[part 2 of 2: package /ComponentTypes]
AUTOSAR XML (schema 00046)
package /ComponentTypes  (continued)
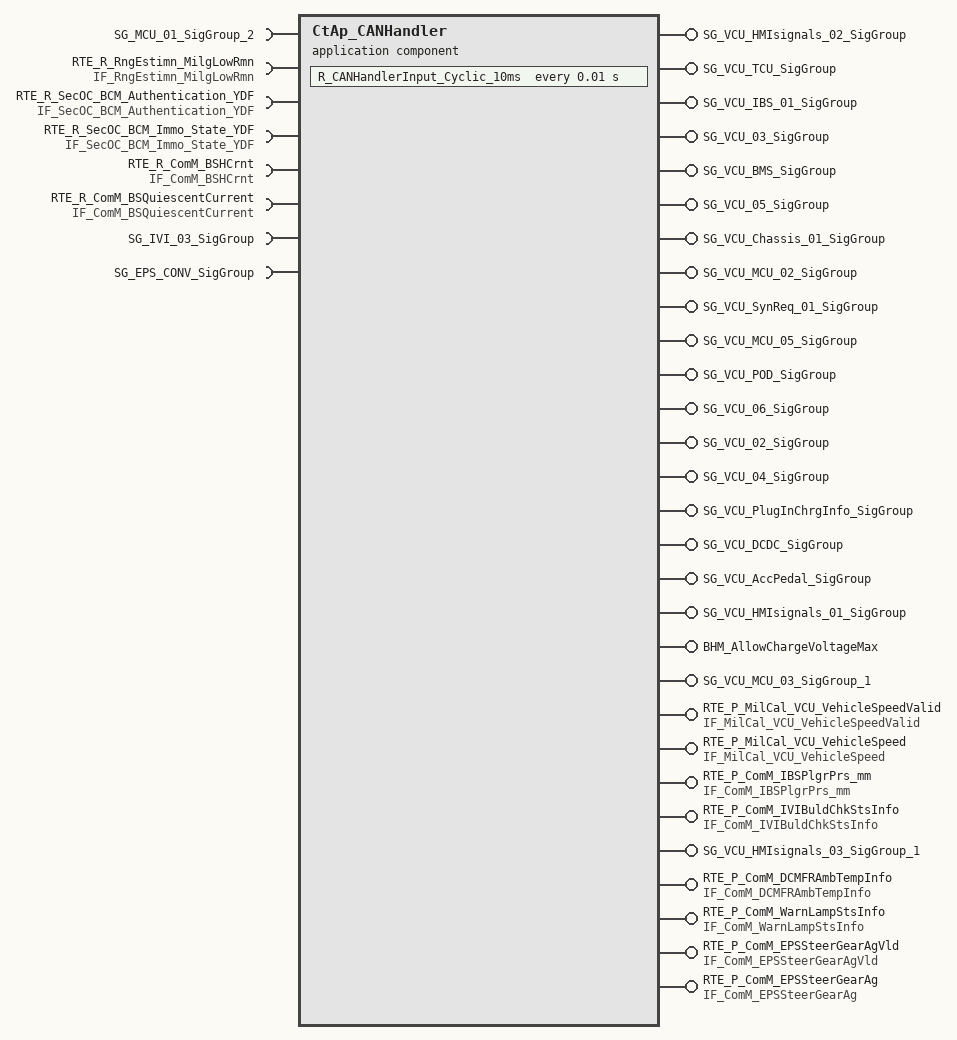
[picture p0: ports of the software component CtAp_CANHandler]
  application sw component type CtAp_CANHandler  (continued)
    19 x provide port:
      SG_VCU_HMIsignals_02_SigGroup: nonqueued-sender-com-spec{data-element=SG_VCU_HMIsignals_02_SigGroup, uses-end-to-end-protection=true, init-value=fields=[Checksum_318:0, MessageCounter_318:0, VCU_DischargeEndSoc:50, VCU_Display_Cur:0, VCU_Display_Power:0, VCU_ForwardVmaxAllowed:0, VCU_maxChargeSOC:255, VCU_MCU_FaultLampReq:0, VCU_SystemReady:0]}, provided-interface=SG_VCU_HMIsignals_02_SigGroup
      SG_VCU_TCU_SigGroup: nonqueued-sender-com-spec{data-element=SG_VCU_TCU_SigGroup, init-value=fields=[VCU_RequestedModeTCU:0, VCU_TCUPowerAllowed:0]}, provided-interface=SG_VCU_TCU_SigGroup
      SG_VCU_IBS_01_SigGroup: nonqueued-sender-com-spec{data-element=SG_VCU_IBS_01_SigGroup, uses-end-to-end-protection=true, init-value=fields=[Checksum_094:0, MessageCounter_094:0, VCU_MotorActualTorque:0, VCU_MotorActualTorqueValid:0, VCU_OPStandstillReq:0, VCU_WheelTrqACT:0, VCU_WheelTrqACTValid:0]}, provided-interface=SG_VCU_IBS_01_SigGroup
      SG_VCU_03_SigGroup: nonqueued-sender-com-spec{data-element=SG_VCU_03_SigGroup, init-value=fields=[VCU_BrakeCompensateStatus:0, VCU_ChargeProcessComment:0, VCU_DCFCCurrent:0, VCU_EnergyV2L:0, VCU_MemoryChargeFault:0]}, provided-interface=SG_VCU_03_SigGroup
      SG_VCU_BMS_SigGroup: nonqueued-sender-com-spec{data-element=SG_VCU_BMS_SigGroup, uses-end-to-end-protection=true, init-value=fields=[Checksum_0D1:0, MessageCounter_0D1:0, VCU_ActDriveMode:0, VCU_BMSTargetThermLevel:0, VCU_DrvModSwitchWarn:0, VCU_HVStatus:0, VCU_LimitLevel:0, VCU_RegenBrakeLightRequest:0, VCU_RegenBrakeLightReqVld:0, VCU_RequestedModeBMS:0, VCU_BMS_Control_of_PosRelay:0, VCU_ChargeStatus:0, VCU_IsoMeasurementSwitch:1]}, provided-interface=SG_VCU_BMS_SigGroup
      SG_VCU_05_SigGroup: nonqueued-sender-com-spec{data-element=SG_VCU_05_SigGroup, init-value=fields=[VCU_MaximumOutputCurrent:0, VCU_MaximumOutputVoltage:0, VCU_MinimumOutputCurrent:0, VCU_MinimumOutputVoltage:0]}, provided-interface=SG_VCU_05_SigGroup
      SG_VCU_Chassis_01_SigGroup: nonqueued-sender-com-spec{data-element=SG_VCU_Chassis_01_SigGroup, uses-end-to-end-protection=true, init-value=fields=[Checksum_0D3:0, MessageCounter_0D3:0, VCU_ADASOverride:0, VCU_APSTorqueRequestActive:0, VCU_APSTorqueRequestAvailable:0, VCU_BrakeCompensateWarn:0, VCU_DecelerationReq:0, VCU_DecelerationReqactive:0, VCU_DriverTorqueRequest:0, VCU_EnergyManagementWarn:0, VCU_RegenTorqueCap:0, VCU_RegenTorqueCapValid:0, VCU_RegStatus:0, VCU_TorqueRequestActive:0, VCU_TorqueRequestAvailable:0]}, provided-interface=SG_VCU_Chassis_01_SigGroup
      SG_VCU_MCU_02_SigGroup: nonqueued-sender-com-spec{data-element=SG_VCU_MCU_02_SigGroup, init-value=fields=[VCU_MaxSpdLimit:32767, VCU_MCUActHeatPwr:0, VCU_MotorSpdReq:32767]}, provided-interface=SG_VCU_MCU_02_SigGroup
      SG_VCU_SynReq_01_SigGroup: nonqueued-sender-com-spec{data-element=SG_VCU_SynReq_01_SigGroup, init-value=fields=VCU_SynRequest:16777215}, provided-interface=SG_VCU_SynReq_01_SigGroup
      SG_VCU_MCU_05_SigGroup: nonqueued-sender-com-spec{data-element=SG_VCU_MCU_05_SigGroup, init-value=fields=[VCU_MaxTorqueGradient:0, VCU_MaxTorqueLimit:0, VCU_MinTorqueLimit:0, VCU_CreepTorque:0, VCU_SpdLimitActTorque:0]}, provided-interface=SG_VCU_MCU_05_SigGroup
      SG_VCU_POD_SigGroup: nonqueued-sender-com-spec{data-element=SG_VCU_POD_SigGroup, init-value=fields=[VCU_Enable_DC_Relay:1, VCU_EnableOBC:0, VCU_OBC_ChargeCurrentCommand:0, VCU_OBC_Control_of_em_lock:1, VCU_OBC_Control_of_S2_SW:1]}, provided-interface=SG_VCU_POD_SigGroup
      SG_VCU_06_SigGroup: nonqueued-sender-com-spec{data-element=SG_VCU_06_SigGroup, init-value=fields=[VCU_ChargeEnergy:0, VCU_ChargeTime:0, VCU_DisChgPowerLimit:0, VCU_DisplayMileage:0, VCU_MCUPower:0, VCU_PermitPackPTC:0]}, provided-interface=SG_VCU_06_SigGroup
      SG_VCU_02_SigGroup: nonqueued-sender-com-spec{data-element=SG_VCU_02_SigGroup, init-value=fields=[VCU_BS_IBSBatSOC:80, VCU_BS_LV_Batt:0, VCU_BS_Current:0, VCU_BS_IndicatorSts:0, VCU_WakeUpStatus:0]}, provided-interface=SG_VCU_02_SigGroup
      SG_VCU_04_SigGroup: nonqueued-sender-com-spec{data-element=SG_VCU_04_SigGroup, init-value=fields=[VCU_ForwardVmaxlimitStatus:0, VCU_ManuallyUnlockComment:0]}, provided-interface=SG_VCU_04_SigGroup
      SG_VCU_PlugInChrgInfo_SigGroup: nonqueued-sender-com-spec{data-element=SG_VCU_PlugInChrgInfo_SigGroup, init-value=fields=[VCU_ChargeEndReason:0, VCU_DischargeEndReason:0, VCU_HVConnectFault:0, VCU_RemainChrgTime:0]}, provided-interface=SG_VCU_PlugInChrgInfo_SigGroup
      SG_VCU_DCDC_SigGroup: nonqueued-sender-com-spec{data-element=SG_VCU_DCDC_SigGroup, init-value=fields=[VCU_DCDCPowerLimit:0, VCU_RequestedModeDCDC:0, VCU_VoltageDemandLV:0]}, provided-interface=SG_VCU_DCDC_SigGroup
      SG_VCU_AccPedal_SigGroup: nonqueued-sender-com-spec{data-element=SG_VCU_AccPedal_SigGroup, uses-end-to-end-protection=true, init-value=fields=[Checksum_0D2:0, MessageCounter_0D2:0, VCU_AccelerationPedal:0, VCU_AccelerationPedalValid:0, VCU_EPBReq:0, VCU_Kickdown:0, VCU_TargetGear:0, VCU_VehicleSpeed:0, VCU_VehicleSpeedValid:0, VCU_VLCTorqueRequestActive:0, VCU_VLCTorqueRequestAvailable:0, VCU_VirtualACPedal:0, VCU_VirtualACPedalValid:0]}, provided-interface=SG_VCU_AccPedal_SigGroup
      SG_VCU_HMIsignals_01_SigGroup: nonqueued-sender-com-spec{data-element=SG_VCU_HMIsignals_01_SigGroup, uses-end-to-end-protection=true, init-value=fields=[Checksum_317:0, MessageCounter_317:0, VCU_CriSysFailure:0, VCU_DCDCFail:0, VCU_DriveMotOvrTemp:0, VCU_HVBatCriFail:0, VCU_HVBatOvrTemp:0, VCU_HVILError:0, VCU_HVInsulResFault:0, VCU_InvldGearSel:0, VCU_LimpHome:0, VCU_PlugStatus:0, VCU_ReachLimitStd:0, VCU_MileagelowRemind:0]}, provided-interface=SG_VCU_HMIsignals_01_SigGroup
      BHM_AllowChargeVoltageMax: nonqueued-sender-com-spec{data-element=BHM_AllowChargeVoltageMax, init-value=0}, provided-interface=BHM_AllowChargeVoltageMax
    require port SG_MCU_01_SigGroup_2: nonqueued-receiver-com-spec{data-element=SG_MCU_01_SigGroup, uses-end-to-end-protection=true, enable-update=true, filter=data-filter-type=ALWAYS, init-value=fields=[MCU_ActTrqValid:0, MCU_ActualSpeed:32767, MCU_ActualSpeedValid:0, MCU_ActualTorque:1023, MCU_IsCurr:1023, MCU_UdcCurr:0, Checksum_098:0, MessageCounter_098:0]}, required-interface=SG_MCU_01_SigGroup_2
    provide port SG_VCU_MCU_03_SigGroup_1: nonqueued-sender-com-spec{data-element=SG_VCU_MCU_03_SigGroup, uses-end-to-end-protection=true, init-value=fields=[Checksum_095:0, MessageCounter_095:0, VCU_ActualGear:0, VCU_BrakepedalStatus:0, VCU_KL15eOn:0, VCU_MCUDesiredTorque:0, VCU_MCUSurgeDamperState:0, VCU_PWTErrorLevel:0, VCU_RequestedModeMCU:0, VCU_TCSActive:0, VCU_TrqThresholdDampgCtl:0]}, provided-interface=SG_VCU_MCU_03_SigGroup_1
    require port RTE_R_RngEstimn_MilgLowRmn: nonqueued-receiver-com-spec{data-element=tec_RngEstimn_MilgLowRmn, filter=data-filter-type=ALWAYS, init-value=0}, required-interface=IF_RngEstimn_MilgLowRmn
    provide port RTE_P_MilCal_VCU_VehicleSpeedValid: nonqueued-sender-com-spec{data-element=tec_MilCal_VCU_VehicleSpeedValid, init-value=0}, provided-interface=IF_MilCal_VCU_VehicleSpeedValid
    provide port RTE_P_MilCal_VCU_VehicleSpeed: nonqueued-sender-com-spec{data-element=tec_MilCal_VCU_VehicleSpeed, init-value=0}, provided-interface=IF_MilCal_VCU_VehicleSpeed
    provide port RTE_P_ComM_IBSPlgrPrs_mm: nonqueued-sender-com-spec{data-element=tec_ComM_IBSPlgrPrs_mm, init-value=0}, provided-interface=IF_ComM_IBSPlgrPrs_mm
    require port RTE_R_SecOC_BCM_Authentication_YDF: nonqueued-receiver-com-spec{data-element=BCM_Authentication_YDF, enable-update=true, filter=data-filter-type=ALWAYS, init-value=0}, required-interface=IF_SecOC_BCM_Authentication_YDF
    require port RTE_R_SecOC_BCM_Immo_State_YDF: nonqueued-receiver-com-spec{data-element=BCM_Immo_State_YDF, enable-update=true, filter=data-filter-type=ALWAYS, init-value=0}, required-interface=IF_SecOC_BCM_Immo_State_YDF
    provide port RTE_P_ComM_IVIBuldChkStsInfo: nonqueued-sender-com-spec{data-element=tec_ComM_IVIBuldChkStsInfo, init-value=0}, provided-interface=IF_ComM_IVIBuldChkStsInfo
    require port RTE_R_ComM_BSHCrnt: nonqueued-receiver-com-spec{data-element=tec_ComM_BSHCrnt, filter=data-filter-type=ALWAYS, init-value=0}, required-interface=IF_ComM_BSHCrnt
    require port RTE_R_ComM_BSQuiescentCurrent: nonqueued-receiver-com-spec{data-element=tec_ComM_BSQuiescentCurrent, filter=data-filter-type=ALWAYS, init-value=0}, required-interface=IF_ComM_BSQuiescentCurrent
    require port SG_IVI_03_SigGroup: nonqueued-receiver-com-spec{data-element=SG_IVI_03_SigGroup, init-value=fields=[Checksum_0F9:0, IVI_BulbCheckSts:0, IVI_SFIabnormalSts:0, IVI_SFIDippedBeamSet:0, MessageCounter_0F9:0]}, required-interface=SG_IVI_03_SigGroup
    5 x provide port:
      SG_VCU_HMIsignals_03_SigGroup_1: nonqueued-sender-com-spec{data-element=SG_VCU_HMIsignals_03_SigGroup, init-value=fields=[VCU_Display_voltage:0, VCU_BS_HCurrent:2047.9375, VCU_BS_QuiescentCurrent:0.99609375]}, provided-interface=SG_VCU_HMIsignals_03_SigGroup_1
      RTE_P_ComM_DCMFRAmbTempInfo: nonqueued-sender-com-spec{data-element=tec_ComM_DCMFRAmbTempInfo, init-value=0}, provided-interface=IF_ComM_DCMFRAmbTempInfo
      RTE_P_ComM_WarnLampStsInfo: nonqueued-sender-com-spec{data-element=tec_ComM_WarnLampStsInfo, init-value=0}, provided-interface=IF_ComM_WarnLampStsInfo
      RTE_P_ComM_EPSSteerGearAgVld: nonqueued-sender-com-spec{data-element=tec_ComM_EPSSteerGearAgVld, init-value=0}, provided-interface=IF_ComM_EPSSteerGearAgVld
      RTE_P_ComM_EPSSteerGearAg: nonqueued-sender-com-spec{data-element=tec_ComM_EPSSteerGearAg, init-value=0}, provided-interface=IF_ComM_EPSSteerGearAg
    require port SG_EPS_CONV_SigGroup: nonqueued-receiver-com-spec{data-element=SG_EPS_CONV_SigGroup, uses-end-to-end-protection=true, enable-update=true, init-value=fields=[Checksum_0F0:0, EPS_ModeChangeEnable:0, EPS_ModeFb:0, EPS_SteeringGearAngle:0, EPS_SteeringGearAngleSpd:0, EPS_SteeringGearAngleSpdValid:0, EPS_SteeringGearAngleValid:0, EPS_TorsionBarTorque:0, EPS_TorsionBarTorqueValid:0, EPS_WarningLamp:0, MessageCounter_0F0:0]}, required-interface=SG_EPS_CONV_SigGroup
    behavior CtAp_CANHandler_InternalBehavior
      timing event TMT_R_CANHandler_Cyclic_10ms: start-on-event=R_CANHandlerInput_Cyclic_10ms, period=0.01
      init event CtAp_CANHandler_InitEvent: start-on-event=R_CANHandler_Init
      11 x timing event:
        TMT_R_CANHandler_Cyclic_50ms: start-on-event=R_CANHandlerInput_Cyclic_50ms, period=0.05
        TMT_R_CANHandler_Cyclic_20ms: start-on-event=R_CANHandlerInput_Cyclic_20ms, period=0.02
        TMT_R_CANHandler_Cyclic_100ms: start-on-event=R_CANHandlerInput_Cyclic_100ms, period=0.1
        TMT_R_CANHandler_Cyclic_200ms: start-on-event=R_CANHandlerInput_Cyclic_200ms, period=0.2
        TMT_R_CANHandler_Cyclic_500ms: start-on-event=R_CANHandlerInput_Cyclic_500ms, period=0.5
        TMT_R_CANHandler_Cyclic_1000ms: start-on-event=R_CANHandlerInput_Cyclic_1000ms, period=1
        TMT_R_CANHandlerOutput_Cyclic_10ms: start-on-event=R_CANHandlerOutput_Cyclic_10ms, period=0.01
        TMT_R_CANHandlerOutput_Cyclic_20ms: start-on-event=R_CANHandlerOutput_Cyclic_20ms, period=0.02
        TMT_R_CANHandlerOutput_Cyclic_50ms: start-on-event=R_CANHandlerOutput_Cyclic_50ms, period=0.05
        TMT_R_CANHandlerOutput_Cyclic_100ms: start-on-event=R_CANHandlerOutput_Cyclic_100ms, period=0.1
        TMT_R_CANHandlerOutput_Cyclic_200ms: start-on-event=R_CANHandlerOutput_Cyclic_200ms, period=0.2
      13 x runnable:
        R_CANHandlerInput_Cyclic_10ms
          data-receive-point-by-arguments:
            7 x access:
              REC_RTE_R_ComM_CANBusOffInfo_Bus_tec_ComM_CHCANBusOffInfo_Bus: accessed-variable=RTE_R_ComM_CANBusOffInfo_Bus.tec_ComM_CHCANBusOffInfo_Bus
              REC_RTE_R_ComM_CANBusOffInfo_Bus_tec_ComM_EPTCANBusOffInfo_Bus: accessed-variable=RTE_R_ComM_CANBusOffInfo_Bus.tec_ComM_EPTCANBusOffInfo_Bus
              REC_RTE_R_DiagApp_DisableDCMReqInfo_tec_DiagApp_DisableDCMReqInfo: accessed-variable=RTE_R_DiagApp_DisableDCMReqInfo.tec_DiagApp_DisableDCMReqInfo
              REC_RTE_R_LvMgmt_BSBattUDcNorm_Flg_tec_LvMgmt_BSBattUDcNorm_Flg: accessed-variable=RTE_R_LvMgmt_BSBattUDcNorm_Flg.tec_LvMgmt_BSBattUDcNorm_Flg
              REC_RTE_R_LvMgmt_KL15ActSts_Flg_tec_LvMgmt_KL15ActSts_Flg: accessed-variable=RTE_R_LvMgmt_KL15ActSts_Flg.tec_LvMgmt_KL15ActSts_Flg
              REC_SG_IBS_VCU_MotorControl_SigGroup_SG_IBS_VCU_MotorControl_SigGroup: accessed-variable=SG_IBS_VCU_MotorControl_SigGroup_CAN.SG_IBS_VCU_MotorControl_SigGroup
              REC_SG_MCU_01_SigGroup_2_SG_MCU_01_SigGroup: accessed-variable=SG_MCU_01_SigGroup_2.SG_MCU_01_SigGroup
          data-send-points:
            20 x access:
              SEND_RTE_P_ComM_IBSVCUMotCtrlMsgErrInfo_Bus_tec_ComM_IBSVCUMotCtrlCRCDTCInfo_Bus: accessed-variable=RTE_P_ComM_IBSVCUMotCtrlMsgErrInfo_Bus.tec_ComM_IBSVCUMotCtrlCRCDTCInfo_Bus
              SEND_RTE_P_ComM_IBSVCUMotCtrlMsgErrInfo_Bus_tec_ComM_IBSVCUMotCtrlCRCInfo_Bus: accessed-variable=RTE_P_ComM_IBSVCUMotCtrlMsgErrInfo_Bus.tec_ComM_IBSVCUMotCtrlCRCInfo_Bus
              SEND_RTE_P_ComM_IBSVCUMotCtrlMsgErrInfo_Bus_tec_ComM_IBSVCUMotCtrlE2ETimeoutInfo_Bus: accessed-variable=RTE_P_ComM_IBSVCUMotCtrlMsgErrInfo_Bus.tec_ComM_IBSVCUMotCtrlE2ETimeoutInfo_Bus
              SEND_RTE_P_ComM_IBSVCUMotCtrlMsgErrInfo_Bus_tec_ComM_IBSVCUMotCtrlTimeoutDTCInfo_Bus: accessed-variable=RTE_P_ComM_IBSVCUMotCtrlMsgErrInfo_Bus.tec_ComM_IBSVCUMotCtrlTimeoutDTCInfo_Bus
              SEND_RTE_P_ComM_IBSVCUMotCtrlMsgErrInfo_Bus_tec_ComM_IBSVCUMotCtrlTimeoutInfo_Bus: accessed-variable=RTE_P_ComM_IBSVCUMotCtrlMsgErrInfo_Bus.tec_ComM_IBSVCUMotCtrlTimeoutInfo_Bus
              SEND_RTE_P_ComM_MCU01MsgErrInfo_Bus_tec_ComM_MCU01CRCDTCInfo_Bus: accessed-variable=RTE_P_ComM_MCU01MsgErrInfo_Bus.tec_ComM_MCU01CRCDTCInfo_Bus
              SEND_RTE_P_ComM_MCU01MsgErrInfo_Bus_tec_ComM_MCU01CRCInfo_Bus: accessed-variable=RTE_P_ComM_MCU01MsgErrInfo_Bus.tec_ComM_MCU01CRCInfo_Bus
              SEND_RTE_P_ComM_MCU01MsgErrInfo_Bus_tec_ComM_MCU01E2ETimeoutInfo_Bus: accessed-variable=RTE_P_ComM_MCU01MsgErrInfo_Bus.tec_ComM_MCU01E2ETimeoutInfo_Bus
              SEND_RTE_P_ComM_MCU01MsgErrInfo_Bus_tec_ComM_MCU01TimeoutDTCInfo_Bus: accessed-variable=RTE_P_ComM_MCU01MsgErrInfo_Bus.tec_ComM_MCU01TimeoutDTCInfo_Bus
              SEND_RTE_P_ComM_MCU01MsgErrInfo_Bus_tec_ComM_MCU01TimeoutInfo_Bus: accessed-variable=RTE_P_ComM_MCU01MsgErrInfo_Bus.tec_ComM_MCU01TimeoutInfo_Bus
              SEND_RTE_P_ComM_MCUIDc_A_tec_ComM_MCUIDc_A: accessed-variable=RTE_P_ComM_MCUIDc_A.tec_ComM_MCUIDc_A
              SEND_RTE_P_ComM_MCUUDc_V_tec_ComM_MCUUDc_V: accessed-variable=RTE_P_ComM_MCUUDc_V.tec_ComM_MCUUDc_V
              SEND_RTE_P_ComM_MotActSpd_rpm_tec_ComM_MotActSpd_rpm: accessed-variable=RTE_P_ComM_MotActSpd_rpm.tec_ComM_MotActSpd_rpm
              SEND_RTE_P_ComM_MotActTqVld_Flg_tec_ComM_MotActTqVld_Flg: accessed-variable=RTE_P_ComM_MotActTqVld_Flg.tec_ComM_MotActTqVld_Flg
              SEND_RTE_P_ComM_MotActTq_Nm_tec_ComM_MotActTq_Nm: accessed-variable=RTE_P_ComM_MotActTq_Nm.tec_ComM_MotActTq_Nm
              SEND_RTE_P_ComM_IBSReqIncTqSts_Flg_tec_ComM_IBSReqIncTqSts_Flg: accessed-variable=RTE_P_ComM_IBSReqIncTqSts_Flg.tec_ComM_IBSReqIncTqSts_Flg
              SEND_RTE_P_ComM_IBSReqIncTq_Nm_tec_ComM_IBSReqIncTq_Nm: accessed-variable=RTE_P_ComM_IBSReqIncTq_Nm.tec_ComM_IBSReqIncTq_Nm
              SEND_RTE_P_ComM_IBSReqRednTqSts_Flg_tec_ComM_IBSReqRednTqSts_Flg: accessed-variable=RTE_P_ComM_IBSReqRednTqSts_Flg.tec_ComM_IBSReqRednTqSts_Flg
              SEND_RTE_P_ComM_IBSReqRednTq_Nm_tec_ComM_IBSReqRednTq_Nm: accessed-variable=RTE_P_ComM_IBSReqRednTq_Nm.tec_ComM_IBSReqRednTq_Nm
              SEND_RTE_P_ComM_MotActSpdVld_Flg_tec_ComM_MotActSpdVld_Flg: accessed-variable=RTE_P_ComM_MotActSpdVld_Flg.tec_ComM_MotActSpdVld_Flg
        R_CANHandler_Init
        R_CANHandlerInput_Cyclic_50ms
        R_CANHandlerInput_Cyclic_20ms
          data-receive-point-by-arguments:
            59 x access:
              REC_RTE_R_ComM_CGWPNC2_tec_ComM_CGWPNC2: accessed-variable=RTE_R_ComM_CGWPNC2.tec_ComM_CGWPNC2
              REC_RTE_R_ComM_CGWPNC13_tec_ComM_CGWPNC13: accessed-variable=RTE_R_ComM_CGWPNC13.tec_ComM_CGWPNC13
              REC_RTE_R_ComM_CGWPNC14_tec_ComM_CGWPNC14: accessed-variable=RTE_R_ComM_CGWPNC14.tec_ComM_CGWPNC14
              REC_RTE_R_ComM_CGWPNC16_tec_ComM_CGWPNC16: accessed-variable=RTE_R_ComM_CGWPNC16.tec_ComM_CGWPNC16
              REC_RTE_R_ComM_CGWPNC21_tec_ComM_CGWPNC21: accessed-variable=RTE_R_ComM_CGWPNC21.tec_ComM_CGWPNC21
              REC_RTE_R_ComM_CGWPNC{4..6}_tec_ComM_CGWPNC{4..6}: accessed-variable=RTE_R_ComM_CGWPNC{4..6}.tec_ComM_CGWPNC{4..6}
              REC_RTE_R_ComM_VCUPNC13_tec_ComM_VCUPNC13: accessed-variable=RTE_R_ComM_VCUPNC13.tec_ComM_VCUPNC13
              REC_RTE_R_ComM_VCUPNC14_tec_ComM_VCUPNC14: accessed-variable=RTE_R_ComM_VCUPNC14.tec_ComM_VCUPNC14
              REC_RTE_R_ComM_VCUPNC16_tec_ComM_VCUPNC16: accessed-variable=RTE_R_ComM_VCUPNC16.tec_ComM_VCUPNC16
              REC_RTE_R_ComM_VCUPNC2_tec_ComM_VCUPNC2: accessed-variable=RTE_R_ComM_VCUPNC2.tec_ComM_VCUPNC2
              REC_RTE_R_ComM_VCUPNC21_tec_ComM_VCUPNC21: accessed-variable=RTE_R_ComM_VCUPNC21.tec_ComM_VCUPNC21
              REC_RTE_R_ComM_VCUPNC{4..6}_tec_ComM_VCUPNC{4..6}: accessed-variable=RTE_R_ComM_VCUPNC{4..6}.tec_ComM_VCUPNC{4..6}
              REC_RTE_R_ComM_BMSPNC16_tec_ComM_BMSPNC16: accessed-variable=RTE_R_ComM_BMSPNC16.tec_ComM_BMSPNC16
              REC_RTE_R_ComM_CANBusOffInfo_Bus_tec_ComM_CHCANBusOffInfo_Bus: accessed-variable=RTE_R_ComM_CANBusOffInfo_Bus.tec_ComM_CHCANBusOffInfo_Bus
              REC_RTE_R_ComM_CANBusOffInfo_Bus_tec_ComM_EPTCANBusOffInfo_Bus: accessed-variable=RTE_R_ComM_CANBusOffInfo_Bus.tec_ComM_EPTCANBusOffInfo_Bus
              REC_RTE_R_DCChrMgmt_DcChrgStrt_Flg_tec_DCChrMgmt_DcChrgStrt_Flg: accessed-variable=RTE_R_DCChrMgmt_DcChrgStrt_Flg.tec_DCChrMgmt_DcChrgStrt_Flg
              REC_RTE_R_DiagApp_DisableDCMReqInfo_tec_DiagApp_DisableDCMReqInfo: accessed-variable=RTE_R_DiagApp_DisableDCMReqInfo.tec_DiagApp_DisableDCMReqInfo
              REC_RTE_R_LvMgmt_BSBattUDcNorm_Flg_tec_LvMgmt_BSBattUDcNorm_Flg: accessed-variable=RTE_R_LvMgmt_BSBattUDcNorm_Flg.tec_LvMgmt_BSBattUDcNorm_Flg
              REC_RTE_R_LvMgmt_KL15ActSts_Flg_tec_LvMgmt_KL15ActSts_Flg: accessed-variable=RTE_R_LvMgmt_KL15ActSts_Flg.tec_LvMgmt_KL15ActSts_Flg
              REC_RTE_R_ComM_CGWPNC0_tec_ComM_CGWPNC0: accessed-variable=RTE_R_ComM_CGWPNC0.tec_ComM_CGWPNC0
              REC_RTE_R_ComM_VCUPNC0_tec_ComM_VCUPNC0: accessed-variable=RTE_R_ComM_VCUPNC0.tec_ComM_VCUPNC0
              REC_SG_ACU_01_SigGroup_SG_ACU_01_SigGroup: accessed-variable=SG_ACU_01_SigGroup.SG_ACU_01_SigGroup
              REC_SG_ACU_02_SigGroup_SG_ACU_02_SigGroup: accessed-variable=SG_ACU_02_SigGroup.SG_ACU_02_SigGroup
              REC_SG_BMS_status_02_SigGroup_SG_BMS_status_02_SigGroup: accessed-variable=SG_BMS_status_02_SigGroup.SG_BMS_status_02_SigGroup
              REC_SG_IBS_Torque_SigGroup_SG_IBS_Torque_SigGroup: accessed-variable=SG_IBS_Torque_SigGroup.SG_IBS_Torque_SigGroup
              REC_SG_MCU_02_SigGroup_SG_MCU_02_SigGroup: accessed-variable=SG_MCU_02_SigGroup.SG_MCU_02_SigGroup
              REC_SG_DCM_FR_SigGroup_SG_DCM_FR_SigGroup: accessed-variable=SG_DCM_FR_SigGroup.SG_DCM_FR_SigGroup
              REC_SG_DCM_RL_SigGroup_SG_DCM_RL_SigGroup: accessed-variable=SG_DCM_RL_SigGroup.SG_DCM_RL_SigGroup
              REC_SG_DCM_RR_SigGroup_SG_DCM_RR_SigGroup: accessed-variable=SG_DCM_RR_SigGroup.SG_DCM_RR_SigGroup
              REC_SG_PRND_SigGroup_SG_PRND_SigGroup: accessed-variable=SG_PRND_SigGroup.SG_PRND_SigGroup
              REC_SG_SGW_04_SigGroup_SG_SGW_04_SigGroup: accessed-variable=SG_SGW_04_SigGroup.SG_SGW_04_SigGroup
              REC_SG_SGW_17_SigGroup_SG_SGW_17_SigGroup: accessed-variable=SG_SGW_17_SigGroup.SG_SGW_17_SigGroup
              REC_SG_IVI_01_SigGroup_SG_IVI_01_SigGroup: accessed-variable=SG_IVI_01_SigGroup.SG_IVI_01_SigGroup
              REC_SG_SGW_IBS_01_SigGroup_SG_SGW_IBS_01_SigGroup: accessed-variable=SG_SGW_IBS_01_SigGroup.SG_SGW_IBS_01_SigGroup
              REC_SG_SGW_PT_01_SigGroup_SG_SGW_PT_01_SigGroup: accessed-variable=SG_SGW_PT_01_SigGroup.SG_SGW_PT_01_SigGroup
              REC_SG_SGW_VCU_01_SigGroup_SG_SGW_VCU_01_SigGroup: accessed-variable=SG_SGW_VCU_01_SigGroup.SG_SGW_VCU_01_SigGroup
              REC_SG_ACU_info_SigGroup_SG_ACU_info_SigGroup: accessed-variable=SG_ACU_info_SigGroup.SG_ACU_info_SigGroup
              REC_SG_ADCU_ACC_02_SigGroup_SG_ADCU_ACC_02_SigGroup: accessed-variable=SG_ADCU_ACC_02_SigGroup.SG_ADCU_ACC_02_SigGroup
              REC_SG_ADCU_APS_01_SigGroup_SG_ADCU_APS_01_SigGroup: accessed-variable=SG_ADCU_APS_01_SigGroup.SG_ADCU_APS_01_SigGroup
              REC_SG_ADCU_AEB_01_SigGroup_SG_ADCU_AEB_01_SigGroup: accessed-variable=SG_ADCU_AEB_01_SigGroup.SG_ADCU_AEB_01_SigGroup
              REC_SG_BMS_status_01_SigGroup_SG_BMS_status_01_SigGroup: accessed-variable=SG_BMS_status_01_SigGroup.SG_BMS_status_01_SigGroup
              REC_SG_IBS_APS_SigGroup_SG_IBS_APS_SigGroup: accessed-variable=SG_IBS_APS_SigGroup.SG_IBS_APS_SigGroup
              REC_SG_IBS_Status_{02..06}_SigGroup_SG_IBS_Status_{02..06}_SigGroup: accessed-variable=SG_IBS_Status_{02..06}_SigGroup.SG_IBS_Status_{02..06}_SigGroup
              REC_SG_SGW_01_SigGroup_SG_SGW_01_SigGroup: accessed-variable=SG_SGW_01_SigGroup.SG_SGW_01_SigGroup
              REC_SG_IBS_WheelSpeed_01_SigGroup_SG_IBS_WheelSpeed_01_SigGroup: accessed-variable=SG_IBS_WheelSpeed_01_SigGroup.SG_IBS_WheelSpeed_01_SigGroup
              REC_SG_IBS_WheelSpeed_02_SigGroup_SG_IBS_WheelSpeed_02_SigGroup: accessed-variable=SG_IBS_WheelSpeed_02_SigGroup.SG_IBS_WheelSpeed_02_SigGroup
              REC_SG_IBS_Status_01_SigGroup_SG_IBS_Status_01_SigGroup: accessed-variable=SG_IBS_Status_01_SigGroup.SG_IBS_Status_01_SigGroup
              REC_SG_IBS_ACC_SigGroup_SG_IBS_ACC_SigGroup: accessed-variable=SG_IBS_ACC_SigGroup.SG_IBS_ACC_SigGroup
              REC_SG_IVI_03_SigGroup_SG_IVI_03_SigGroup: accessed-variable=SG_IVI_03_SigGroup.SG_IVI_03_SigGroup
              REC_SG_CGW_02_SigGroup_SG_CGW_02_SigGroup: accessed-variable=SG_CGW_02_SigGroup.SG_CGW_02_SigGroup
              REC_SG_EPS_CONV_SigGroup_SG_EPS_CONV_SigGroup: accessed-variable=SG_EPS_CONV_SigGroup.SG_EPS_CONV_SigGroup
          data-send-points:
            172 x access:
              SEND_RTE_P_ComM_ACU01MsgErrInfo_Bus_tec_ComM_ACU01CRCDTCInfo_Bus: accessed-variable=RTE_P_ComM_ACU01MsgErrInfo_Bus.tec_ComM_ACU01CRCDTCInfo_Bus
              SEND_RTE_P_ComM_ACU01MsgErrInfo_Bus_tec_ComM_ACU01TimeoutDTCInfo_Bus: accessed-variable=RTE_P_ComM_ACU01MsgErrInfo_Bus.tec_ComM_ACU01TimeoutDTCInfo_Bus
              SEND_RTE_P_ComM_ACU02MsgErrInfo_Bus_tec_ComM_ACU02CRCDTCInfo_Bus: accessed-variable=RTE_P_ComM_ACU02MsgErrInfo_Bus.tec_ComM_ACU02CRCDTCInfo_Bus
              SEND_RTE_P_ComM_ACU02MsgErrInfo_Bus_tec_ComM_ACU02TimeoutDTCInfo_Bus: accessed-variable=RTE_P_ComM_ACU02MsgErrInfo_Bus.tec_ComM_ACU02TimeoutDTCInfo_Bus
              SEND_RTE_P_ComM_ACUInfoMsgErrInfo_Bus_tec_ComM_ACUInfoTimeoutDTCInfo_Bus: accessed-variable=RTE_P_ComM_ACUInfoMsgErrInfo_Bus.tec_ComM_ACUInfoTimeoutDTCInfo_Bus
              SEND_RTE_P_ComM_ACUInfoMsgErrInfo_Bus_tec_ComM_ACUInfoTimeoutInfo_Bus: accessed-variable=RTE_P_ComM_ACUInfoMsgErrInfo_Bus.tec_ComM_ACUInfoTimeoutInfo_Bus
              SEND_RTE_P_ComM_ADCUACC02MsgErrInfo_Bus_tec_ComM_ADCUACC02CRCDTCInfo_Bus: accessed-variable=RTE_P_ComM_ADCUACC02MsgErrInfo_Bus.tec_ComM_ADCUACC02CRCDTCInfo_Bus
              SEND_RTE_P_ComM_ADCUACC02MsgErrInfo_Bus_tec_ComM_ADCUACC02TimeoutDTCInfo_Bus: accessed-variable=RTE_P_ComM_ADCUACC02MsgErrInfo_Bus.tec_ComM_ADCUACC02TimeoutDTCInfo_Bus
              SEND_RTE_P_ComM_ADCUACC02MsgErrInfo_Bus_tec_ComM_ADCUACC02TimeoutInfo_Bus: accessed-variable=RTE_P_ComM_ADCUACC02MsgErrInfo_Bus.tec_ComM_ADCUACC02TimeoutInfo_Bus
              SEND_RTE_P_ComM_BMSSts01ErrInfo_Bus_tec_ComM_BMSSts01CRCDTCInfo_Bus: accessed-variable=RTE_P_ComM_BMSSts01ErrInfo_Bus.tec_ComM_BMSSts01CRCDTCInfo_Bus
              SEND_RTE_P_ComM_BMSSts01ErrInfo_Bus_tec_ComM_BMSSts01CRCInfo_Bus: accessed-variable=RTE_P_ComM_BMSSts01ErrInfo_Bus.tec_ComM_BMSSts01CRCInfo_Bus
              SEND_RTE_P_ComM_BMSSts01ErrInfo_Bus_tec_ComM_BMSSts01E2ETimeoutInfo_Bus: accessed-variable=RTE_P_ComM_BMSSts01ErrInfo_Bus.tec_ComM_BMSSts01E2ETimeoutInfo_Bus
              SEND_RTE_P_ComM_BMSSts01ErrInfo_Bus_tec_ComM_BMSSts01TimeoutDTCInfo_Bus: accessed-variable=RTE_P_ComM_BMSSts01ErrInfo_Bus.tec_ComM_BMSSts01TimeoutDTCInfo_Bus
              SEND_RTE_P_ComM_BMSSts01ErrInfo_Bus_tec_ComM_BMSSts01TimeoutInfo_Bus: accessed-variable=RTE_P_ComM_BMSSts01ErrInfo_Bus.tec_ComM_BMSSts01TimeoutInfo_Bus
              SEND_RTE_P_ComM_IBSACCMsgErrInfo_Bus_tec_ComM_IBSACCCRCDTCInfo_Bus: accessed-variable=RTE_P_ComM_IBSACCMsgErrInfo_Bus.tec_ComM_IBSACCCRCDTCInfo_Bus
              SEND_RTE_P_ComM_IBSACCMsgErrInfo_Bus_tec_ComM_IBSACCCRCInfo_Bus: accessed-variable=RTE_P_ComM_IBSACCMsgErrInfo_Bus.tec_ComM_IBSACCCRCInfo_Bus
              SEND_RTE_P_ComM_IBSACCMsgErrInfo_Bus_tec_ComM_IBSACCE2ETimeoutInfo_Bus: accessed-variable=RTE_P_ComM_IBSACCMsgErrInfo_Bus.tec_ComM_IBSACCE2ETimeoutInfo_Bus
              SEND_RTE_P_ComM_IBSACCMsgErrInfo_Bus_tec_ComM_IBSACCTimeoutDTCInfo_Bus: accessed-variable=RTE_P_ComM_IBSACCMsgErrInfo_Bus.tec_ComM_IBSACCTimeoutDTCInfo_Bus
              SEND_RTE_P_ComM_IBSSts01MsgErrInfo_Bus_tec_ComM_IBSSts01CRCDTCInfo_Bus: accessed-variable=RTE_P_ComM_IBSSts01MsgErrInfo_Bus.tec_ComM_IBSSts01CRCDTCInfo_Bus
              SEND_RTE_P_ComM_IBSSts01MsgErrInfo_Bus_tec_ComM_IBSSts01CRCInfo_Bus: accessed-variable=RTE_P_ComM_IBSSts01MsgErrInfo_Bus.tec_ComM_IBSSts01CRCInfo_Bus
              SEND_RTE_P_ComM_IBSSts01MsgErrInfo_Bus_tec_ComM_IBSSts01E2ETimeoutInfo_Bus: accessed-variable=RTE_P_ComM_IBSSts01MsgErrInfo_Bus.tec_ComM_IBSSts01E2ETimeoutInfo_Bus
              SEND_RTE_P_ComM_IBSSts01MsgErrInfo_Bus_tec_ComM_IBSSts01TimeoutDTCInfo_Bus: accessed-variable=RTE_P_ComM_IBSSts01MsgErrInfo_Bus.tec_ComM_IBSSts01TimeoutDTCInfo_Bus
              SEND_RTE_P_ComM_IBSSts02MsgErrInfo_Bus_tec_ComM_IBSSts02CRCDTCInfo_Bus: accessed-variable=RTE_P_ComM_IBSSts02MsgErrInfo_Bus.tec_ComM_IBSSts02CRCDTCInfo_Bus
              SEND_RTE_P_ComM_IBSSts02MsgErrInfo_Bus_tec_ComM_IBSSts02CRCInfo_Bus: accessed-variable=RTE_P_ComM_IBSSts02MsgErrInfo_Bus.tec_ComM_IBSSts02CRCInfo_Bus
              SEND_RTE_P_ComM_IBSSts02MsgErrInfo_Bus_tec_ComM_IBSSts02E2ETimeoutInfo_Bus: accessed-variable=RTE_P_ComM_IBSSts02MsgErrInfo_Bus.tec_ComM_IBSSts02E2ETimeoutInfo_Bus
              SEND_RTE_P_ComM_IBSSts02MsgErrInfo_Bus_tec_ComM_IBSSts02TimeoutDTCInfo_Bus: accessed-variable=RTE_P_ComM_IBSSts02MsgErrInfo_Bus.tec_ComM_IBSSts02TimeoutDTCInfo_Bus
              SEND_RTE_P_ComM_IBSSts03MsgErrInfo_Bus_tec_ComM_IBSSts03CRCDTCInfo_Bus: accessed-variable=RTE_P_ComM_IBSSts03MsgErrInfo_Bus.tec_ComM_IBSSts03CRCDTCInfo_Bus
              SEND_RTE_P_ComM_IBSSts03MsgErrInfo_Bus_tec_ComM_IBSSts03CRCInfo_Bus: accessed-variable=RTE_P_ComM_IBSSts03MsgErrInfo_Bus.tec_ComM_IBSSts03CRCInfo_Bus
              SEND_RTE_P_ComM_IBSSts03MsgErrInfo_Bus_tec_ComM_IBSSts03E2ETimeoutInfo_Bus: accessed-variable=RTE_P_ComM_IBSSts03MsgErrInfo_Bus.tec_ComM_IBSSts03E2ETimeoutInfo_Bus
              SEND_RTE_P_ComM_IBSSts03MsgErrInfo_Bus_tec_ComM_IBSSts03TimeoutDTCInfo_Bus: accessed-variable=RTE_P_ComM_IBSSts03MsgErrInfo_Bus.tec_ComM_IBSSts03TimeoutDTCInfo_Bus
              SEND_RTE_P_ComM_IBSSts05MsgErrInfo_Bus_tec_ComM_IBSSts05CRCDTCInfo_Bus: accessed-variable=RTE_P_ComM_IBSSts05MsgErrInfo_Bus.tec_ComM_IBSSts05CRCDTCInfo_Bus
              SEND_RTE_P_ComM_IBSSts05MsgErrInfo_Bus_tec_ComM_IBSSts05TimeoutDTCInfo_Bus: accessed-variable=RTE_P_ComM_IBSSts05MsgErrInfo_Bus.tec_ComM_IBSSts05TimeoutDTCInfo_Bus
              SEND_RTE_P_ComM_IBSSts05MsgErrInfo_Bus_tec_ComM_IBSSts05TimeoutInfo_Bus: accessed-variable=RTE_P_ComM_IBSSts05MsgErrInfo_Bus.tec_ComM_IBSSts05TimeoutInfo_Bus
              SEND_RTE_P_ComM_IBSSts06MsgErrInfo_Bus_tec_ComM_IBSSts06CRCDTCInfo_Bus: accessed-variable=RTE_P_ComM_IBSSts06MsgErrInfo_Bus.tec_ComM_IBSSts06CRCDTCInfo_Bus
              SEND_RTE_P_ComM_IBSSts06MsgErrInfo_Bus_tec_ComM_IBSSts06TimeoutDTCInfo_Bus: accessed-variable=RTE_P_ComM_IBSSts06MsgErrInfo_Bus.tec_ComM_IBSSts06TimeoutDTCInfo_Bus
              SEND_RTE_P_ComM_IBSTqMsgErrInfo_Bus_tec_ComM_IBSTqCRCDTCInfo_Bus: accessed-variable=RTE_P_ComM_IBSTqMsgErrInfo_Bus.tec_ComM_IBSTqCRCDTCInfo_Bus
              SEND_RTE_P_ComM_IBSTqMsgErrInfo_Bus_tec_ComM_IBSTqCRCInfo_Bus: accessed-variable=RTE_P_ComM_IBSTqMsgErrInfo_Bus.tec_ComM_IBSTqCRCInfo_Bus
              SEND_RTE_P_ComM_IBSTqMsgErrInfo_Bus_tec_ComM_IBSTqE2ETimeoutInfo_Bus: accessed-variable=RTE_P_ComM_IBSTqMsgErrInfo_Bus.tec_ComM_IBSTqE2ETimeoutInfo_Bus
              SEND_RTE_P_ComM_IBSTqMsgErrInfo_Bus_tec_ComM_IBSTqTimeoutDTCInfo_Bus: accessed-variable=RTE_P_ComM_IBSTqMsgErrInfo_Bus.tec_ComM_IBSTqTimeoutDTCInfo_Bus
              SEND_RTE_P_ComM_IBSWhlSpd01MsgErrInfo_Bus_tec_ComM_IBSWhlSpd01CRCDTCInfo_Bus: accessed-variable=RTE_P_ComM_IBSWhlSpd01MsgErrInfo_Bus.tec_ComM_IBSWhlSpd01CRCDTCInfo_Bus
              SEND_RTE_P_ComM_IBSWhlSpd01MsgErrInfo_Bus_tec_ComM_IBSWhlSpd01TimeoutDTCInfo_Bus: accessed-variable=RTE_P_ComM_IBSWhlSpd01MsgErrInfo_Bus.tec_ComM_IBSWhlSpd01TimeoutDTCInfo_Bus
              SEND_RTE_P_ComM_IBSWhlSpd02MsgErrInfo_Bus_tec_ComM_IBSWhlSpd02CRCDTCInfo_Bus: accessed-variable=RTE_P_ComM_IBSWhlSpd02MsgErrInfo_Bus.tec_ComM_IBSWhlSpd02CRCDTCInfo_Bus
              SEND_RTE_P_ComM_IBSWhlSpd02MsgErrInfo_Bus_tec_ComM_IBSWhlSpd02TimeoutDTCInfo_Bus: accessed-variable=RTE_P_ComM_IBSWhlSpd02MsgErrInfo_Bus.tec_ComM_IBSWhlSpd02TimeoutDTCInfo_Bus
              SEND_RTE_P_ComM_IVI01MsgErrInfo_Bus_tec_ComM_IVI01CRCInfo_Bus: accessed-variable=RTE_P_ComM_IVI01MsgErrInfo_Bus.tec_ComM_IVI01CRCInfo_Bus
              SEND_RTE_P_ComM_IVI01MsgErrInfo_Bus_tec_ComM_IVI01E2ETimeoutInfo_Bus: accessed-variable=RTE_P_ComM_IVI01MsgErrInfo_Bus.tec_ComM_IVI01E2ETimeoutInfo_Bus
              SEND_RTE_P_ComM_PRNDMsgErrInfo_Bus_tec_ComM_PRNDCRCDTCInfo_Bus: accessed-variable=RTE_P_ComM_PRNDMsgErrInfo_Bus.tec_ComM_PRNDCRCDTCInfo_Bus
              SEND_RTE_P_ComM_PRNDMsgErrInfo_Bus_tec_ComM_PRNDCRCInfo_Bus: accessed-variable=RTE_P_ComM_PRNDMsgErrInfo_Bus.tec_ComM_PRNDCRCInfo_Bus
              SEND_RTE_P_ComM_PRNDMsgErrInfo_Bus_tec_ComM_PRNDE2ETimeoutInfo_Bus: accessed-variable=RTE_P_ComM_PRNDMsgErrInfo_Bus.tec_ComM_PRNDE2ETimeoutInfo_Bus
              SEND_RTE_P_ComM_PRNDMsgErrInfo_Bus_tec_ComM_PRNDTimeoutDTCInfo_Bus: accessed-variable=RTE_P_ComM_PRNDMsgErrInfo_Bus.tec_ComM_PRNDTimeoutDTCInfo_Bus
              SEND_RTE_P_ComM_PRNDMsgErrInfo_Bus_tec_ComM_PRNDTimeoutInfo_Bus: accessed-variable=RTE_P_ComM_PRNDMsgErrInfo_Bus.tec_ComM_PRNDTimeoutInfo_Bus
              SEND_RTE_P_ComM_SGWPT01MsgErrInfo_Bus_tec_ComM_SGWPT01TimeoutDTCInfo_Bus: accessed-variable=RTE_P_ComM_SGWPT01MsgErrInfo_Bus.tec_ComM_SGWPT01TimeoutDTCInfo_Bus
              SEND_RTE_P_ComM_SGWPT01MsgErrInfo_Bus_tec_ComM_SGWPT01TimeoutInfo_Bus: accessed-variable=RTE_P_ComM_SGWPT01MsgErrInfo_Bus.tec_ComM_SGWPT01TimeoutInfo_Bus
              SEND_RTE_P_ComM_ACUCrashOutpSts_Enum_tec_ComM_ACUCrashOutpSts_Enum: accessed-variable=RTE_P_ComM_ACUCrashOutpSts_Enum.tec_ComM_ACUCrashOutpSts_Enum
              SEND_RTE_P_ComM_BMSBattIDc_A_tec_ComM_BMSBattIDc_A: accessed-variable=RTE_P_ComM_BMSBattIDc_A.tec_ComM_BMSBattIDc_A
              SEND_RTE_P_ComM_BMSErrLvl_Enum_tec_ComM_BMSErrLvl_Enum: accessed-variable=RTE_P_ComM_BMSErrLvl_Enum.tec_ComM_BMSErrLvl_Enum
              SEND_RTE_P_ComM_ApptChrgMdlSts_Enum_tec_ComM_ApptChrgMdlSts_Enum: accessed-variable=RTE_P_ComM_ApptChrgMdlSts_Enum.tec_ComM_ApptChrgMdlSts_Enum
              SEND_RTE_P_ComM_BMSBattHeatIDc_A_tec_ComM_BMSBattHeatIDc_A: accessed-variable=RTE_P_ComM_BMSBattHeatIDc_A.tec_ComM_BMSBattHeatIDc_A
              SEND_RTE_P_ComM_BMSBattUDc_V_tec_ComM_BMSBattUDc_V: accessed-variable=RTE_P_ComM_BMSBattUDc_V.tec_ComM_BMSBattUDc_V
              SEND_RTE_P_ComM_BMSChrgSts_Enum_tec_ComM_BMSChrgSts_Enum: accessed-variable=RTE_P_ComM_BMSChrgSts_Enum.tec_ComM_BMSChrgSts_Enum
              SEND_RTE_P_ComM_BMSHVILSts_Flg_tec_ComM_BMSHVILSts_Flg: accessed-variable=RTE_P_ComM_BMSHVILSts_Flg.tec_ComM_BMSHVILSts_Flg
              SEND_RTE_P_ComM_BMSIRDetnSts_Enum_tec_ComM_BMSIRDetnSts_Enum: accessed-variable=RTE_P_ComM_BMSIRDetnSts_Enum.tec_ComM_BMSIRDetnSts_Enum
              SEND_RTE_P_ComM_BMSInslaErrLvl_Enum_tec_ComM_BMSInslaErrLvl_Enum: accessed-variable=RTE_P_ComM_BMSInslaErrLvl_Enum.tec_ComM_BMSInslaErrLvl_Enum
              SEND_RTE_P_ComM_BMSWrkMod_Enum_tec_ComM_BMSWrkMod_Enum: accessed-variable=RTE_P_ComM_BMSWrkMod_Enum.tec_ComM_BMSWrkMod_Enum
              SEND_RTE_P_ComM_EPBWrkSts_Enum_tec_ComM_EPBWrkSts_Enum: accessed-variable=RTE_P_ComM_EPBWrkSts_Enum.tec_ComM_EPBWrkSts_Enum
              SEND_RTE_P_ComM_GearPBtnFltSts_Flg_tec_ComM_GearPBtnFltSts_Flg: accessed-variable=RTE_P_ComM_GearPBtnFltSts_Flg.tec_ComM_GearPBtnFltSts_Flg
              SEND_RTE_P_ComM_GearPBtn_Enum_tec_ComM_GearPBtn_Enum: accessed-variable=RTE_P_ComM_GearPBtn_Enum.tec_ComM_GearPBtn_Enum
              SEND_RTE_P_ComM_GearRNDBtnFltSts_Flg_tec_ComM_GearRNDBtnFltSts_Flg: accessed-variable=RTE_P_ComM_GearRNDBtnFltSts_Flg.tec_ComM_GearRNDBtnFltSts_Flg
              SEND_RTE_P_ComM_GearRNDBtn_Enum_tec_ComM_GearRNDBtn_Enum: accessed-variable=RTE_P_ComM_GearRNDBtn_Enum.tec_ComM_GearRNDBtn_Enum
              SEND_RTE_P_ComM_IBSAbpActv_Flg_tec_ComM_IBSAbpActv_Flg: accessed-variable=RTE_P_ComM_IBSAbpActv_Flg.tec_ComM_IBSAbpActv_Flg
              SEND_RTE_P_ComM_IBSAebActv_Flg_tec_ComM_IBSAebActv_Flg: accessed-variable=RTE_P_ComM_IBSAebActv_Flg.tec_ComM_IBSAebActv_Flg
              SEND_RTE_P_ComM_IBSDecelReqAvl_Enum_tec_ComM_IBSDecelReqAvl_Enum: accessed-variable=RTE_P_ComM_IBSDecelReqAvl_Enum.tec_ComM_IBSDecelReqAvl_Enum
              SEND_RTE_P_ComM_IBSEscOffSts_Enum_tec_ComM_IBSEscOffSts_Enum: accessed-variable=RTE_P_ComM_IBSEscOffSts_Enum.tec_ComM_IBSEscOffSts_Enum
              SEND_RTE_P_ComM_IBSHdcSts_Enum_tec_ComM_IBSHdcSts_Enum: accessed-variable=RTE_P_ComM_IBSHdcSts_Enum.tec_ComM_IBSHdcSts_Enum
              SEND_RTE_P_ComM_IBSRLMovgDir_Enum_tec_ComM_IBSRLMovgDir_Enum: accessed-variable=RTE_P_ComM_IBSRLMovgDir_Enum.tec_ComM_IBSRLMovgDir_Enum
              SEND_RTE_P_ComM_IBSRLSpdVld_Flg_tec_ComM_IBSRLSpdVld_Flg: accessed-variable=RTE_P_ComM_IBSRLSpdVld_Flg.tec_ComM_IBSRLSpdVld_Flg
              SEND_RTE_P_ComM_IBSRLSpd_kph_tec_ComM_IBSRLSpd_kph: accessed-variable=RTE_P_ComM_IBSRLSpd_kph.tec_ComM_IBSRLSpd_kph
              SEND_RTE_P_ComM_IBSRRMovgDir_Enum_tec_ComM_IBSRRMovgDir_Enum: accessed-variable=RTE_P_ComM_IBSRRMovgDir_Enum.tec_ComM_IBSRRMovgDir_Enum
              SEND_RTE_P_ComM_IBSRRSpdVld_Flg_tec_ComM_IBSRRSpdVld_Flg: accessed-variable=RTE_P_ComM_IBSRRSpdVld_Flg.tec_ComM_IBSRRSpdVld_Flg
              SEND_RTE_P_ComM_IBSRRSpd_kph_tec_ComM_IBSRRSpd_kph: accessed-variable=RTE_P_ComM_IBSRRSpd_kph.tec_ComM_IBSRRSpd_kph
              SEND_RTE_P_ComM_IBSRwuActv_Flg_tec_ComM_IBSRwuActv_Flg: accessed-variable=RTE_P_ComM_IBSRwuActv_Flg.tec_ComM_IBSRwuActv_Flg
              SEND_RTE_P_ComM_IBSTarGearReq_Enum_tec_ComM_IBSTarGearReq_Enum: accessed-variable=RTE_P_ComM_IBSTarGearReq_Enum.tec_ComM_IBSTarGearReq_Enum
              SEND_RTE_P_ComM_IBSTcsActv_Flg_tec_ComM_IBSTcsActv_Flg: accessed-variable=RTE_P_ComM_IBSTcsActv_Flg.tec_ComM_IBSTcsActv_Flg
              SEND_RTE_P_ComM_IBSVdcActv_Flg_tec_ComM_IBSVdcActv_Flg: accessed-variable=RTE_P_ComM_IBSVdcActv_Flg.tec_ComM_IBSVdcActv_Flg
              SEND_RTE_P_ComM_IVIChrgCmd_Enum_tec_ComM_IVIChrgCmd_Enum: accessed-variable=RTE_P_ComM_IVIChrgCmd_Enum.tec_ComM_IVIChrgCmd_Enum
              SEND_RTE_P_ComM_IVIDchaSwtSts_Enum_tec_ComM_IVIDchaSwtSts_Enum: accessed-variable=RTE_P_ComM_IVIDchaSwtSts_Enum.tec_ComM_IVIDchaSwtSts_Enum
              SEND_RTE_P_ComM_IVIDrvModSet_Enum_tec_ComM_IVIDrvModSet_Enum: accessed-variable=RTE_P_ComM_IVIDrvModSet_Enum.tec_ComM_IVIDrvModSet_Enum
              SEND_RTE_P_ComM_IVIFwdMaxVehSpdLmtSwt_Enum_tec_ComM_IVIFwdMaxVehSpdLmtSwt_Enum: accessed-variable=RTE_P_ComM_IVIFwdMaxVehSpdLmtSwt_Enum.tec_ComM_IVIFwdMaxVehSpdLmtSwt_Enum
              SEND_RTE_P_ComM_IVIFwdVehSpdAllwd_Enum_tec_ComM_IVIFwdVehSpdAllwd_Enum: accessed-variable=RTE_P_ComM_IVIFwdVehSpdAllwd_Enum.tec_ComM_IVIFwdVehSpdAllwd_Enum
              SEND_RTE_P_ComM_IVIGearReq_Enum_tec_ComM_IVIGearReq_Enum: accessed-variable=RTE_P_ComM_IVIGearReq_Enum.tec_ComM_IVIGearReq_Enum
              SEND_RTE_P_ComM_IVIMaxChrgSOCSet_pct_tec_ComM_IVIMaxChrgSOCSet_pct: accessed-variable=RTE_P_ComM_IVIMaxChrgSOCSet_pct.tec_ComM_IVIMaxChrgSOCSet_pct
              SEND_RTE_P_ComM_IVIMinDchaSOCSet_Enum_tec_ComM_IVIMinDchaSOCSet_Enum: accessed-variable=RTE_P_ComM_IVIMinDchaSOCSet_Enum.tec_ComM_IVIMinDchaSOCSet_Enum
              SEND_RTE_P_ComM_IVIReqElectcLock_Enum_tec_ComM_IVIReqElectcLock_Enum: accessed-variable=RTE_P_ComM_IVIReqElectcLock_Enum.tec_ComM_IVIReqElectcLock_Enum
              SEND_RTE_P_ComM_IVIRgnLvlSet_Enum_tec_ComM_IVIRgnLvlSet_Enum: accessed-variable=RTE_P_ComM_IVIRgnLvlSet_Enum.tec_ComM_IVIRgnLvlSet_Enum
              SEND_RTE_P_ComM_MCUWrkMod_Enum_tec_ComM_MCUWrkMod_Enum: accessed-variable=RTE_P_ComM_MCUWrkMod_Enum.tec_ComM_MCUWrkMod_Enum
              SEND_RTE_P_ComM_SGWChrgCmd_Enum_tec_ComM_SGWChrgCmd_Enum: accessed-variable=RTE_P_ComM_SGWChrgCmd_Enum.tec_ComM_SGWChrgCmd_Enum
              SEND_RTE_P_ComM_SysIRVal_kOhm_tec_ComM_SysIRVal_kOhm: accessed-variable=RTE_P_ComM_SysIRVal_kOhm.tec_ComM_SysIRVal_kOhm
              SEND_RTE_P_ComM_IBSFLMovgDir_Enum_tec_ComM_IBSFLMovgDir_Enum: accessed-variable=RTE_P_ComM_IBSFLMovgDir_Enum.tec_ComM_IBSFLMovgDir_Enum
              SEND_RTE_P_ComM_IBSFRMovgDir_Enum_tec_ComM_IBSFRMovgDir_Enum: accessed-variable=RTE_P_ComM_IBSFRMovgDir_Enum.tec_ComM_IBSFRMovgDir_Enum
              SEND_RTE_P_ComM_IBSVehSpdVld_Flg_tec_ComM_IBSVehSpdVld_Flg: accessed-variable=RTE_P_ComM_IBSVehSpdVld_Flg.tec_ComM_IBSVehSpdVld_Flg
              SEND_RTE_P_ComM_IBSVehSpd_kph_tec_ComM_IBSVehSpd_kph: accessed-variable=RTE_P_ComM_IBSVehSpd_kph.tec_ComM_IBSVehSpd_kph
              SEND_RTE_P_ComM_ADCUAccMod_Enum_tec_ComM_ADCUAccMod_Enum: accessed-variable=RTE_P_ComM_ADCUAccMod_Enum.tec_ComM_ADCUAccMod_Enum
              SEND_RTE_P_ComM_IBSApsReqTqVld_Enum_tec_ComM_IBSApsReqTqVld_Enum: accessed-variable=RTE_P_ComM_IBSApsReqTqVld_Enum.tec_ComM_IBSApsReqTqVld_Flg
              SEND_RTE_P_ComM_IBSApsReqTq_Nm_tec_ComM_IBSApsReqTq_Nm: accessed-variable=RTE_P_ComM_IBSApsReqTq_Nm.tec_ComM_IBSApsReqTq_Nm
              SEND_RTE_P_ComM_IBSBrkSts_Enum_tec_ComM_IBSBrkSts_Enum: accessed-variable=RTE_P_ComM_IBSBrkSts_Enum.tec_ComM_IBSBrkSts_Enum
              SEND_RTE_P_ComM_IBSRbsReqTqVld_Enum_tec_ComM_IBSRbsReqTqVld_Enum: accessed-variable=RTE_P_ComM_IBSRbsReqTqVld_Enum.tec_ComM_IBSRbsReqTqVld_Enum
              SEND_RTE_P_ComM_IBSRbsReqTq_Nm_tec_ComM_IBSRbsReqTq_Nm: accessed-variable=RTE_P_ComM_IBSRbsReqTq_Nm.tec_ComM_IBSRbsReqTq_Nm
              SEND_RTE_P_ComM_IBSRbsSts_Enum_tec_ComM_IBSRbsSts_Enum: accessed-variable=RTE_P_ComM_IBSRbsSts_Enum.tec_ComM_IBSRbsSts_Enum
              SEND_RTE_P_ComM_IBSVlcActv_Flg_tec_ComM_IBSVlcActv_Flg: accessed-variable=RTE_P_ComM_IBSVlcActv_Flg.tec_ComM_IBSVlcActv_Flg
              SEND_RTE_P_ComM_IBSVlcReqTqVld_Flg_tec_ComM_IBSVlcReqTqVld_Flg: accessed-variable=RTE_P_ComM_IBSVlcReqTqVld_Flg.tec_ComM_IBSVlcReqTqVld_Flg
              SEND_RTE_P_ComM_IBSVlcReqTq_Nm_tec_ComM_IBSVlcReqTq_Nm: accessed-variable=RTE_P_ComM_IBSVlcReqTq_Nm.tec_ComM_IBSVlcReqTq_Nm
              SEND_RTE_P_ComM_IBSAvhSts_Enum_tec_ComM_IBSAvhSts_Enum: accessed-variable=RTE_P_ComM_IBSAvhSts_Enum.tec_ComM_IBSAvhSts_Enum
              SEND_RTE_P_ComM_IBSApsTqActv_Flg_tec_ComM_IBSApsTqActv_Flg: accessed-variable=RTE_P_ComM_IBSApsTqActv_Flg.tec_ComM_IBSApsTqActv_Flg
              SEND_RTE_P_ComM_IBSPlgrPrs_Bar_tec_ComM_IBSPlgrPrs_Bar: accessed-variable=RTE_P_ComM_IBSPlgrPrs_Bar.tec_ComM_IBSPlgrPrs_Bar
              SEND_RTE_P_ComM_IVIEnaBrkCmpMod_Enum_tec_ComM_IVIEnaBrkCmpMod_Enum: accessed-variable=RTE_P_ComM_IVIEnaBrkCmpMod_Enum.tec_ComM_IVIEnaBrkCmpMod_Enum
              SEND_RTE_P_ComM_IVILVLimPopInfo_tec_ComM_IVILVLimPopInfo: accessed-variable=RTE_P_ComM_IVILVLimPopInfo.tec_ComM_IVILVLimPopInfo
              SEND_RTE_P_ComM_BrkFldWarnStsInfo_tec_ComM_BrkFldWarnStsInfo: accessed-variable=RTE_P_ComM_BrkFldWarnStsInfo.tec_ComM_BrkFldWarnStsInfo
              SEND_RTE_P_ComM_DoorFRStsInfo_tec_ComM_DoorFRStsInfo: accessed-variable=RTE_P_ComM_DoorFRStsInfo.tec_ComM_DoorFRStsInfo
              SEND_RTE_P_ComM_DoorRLStsInfo_tec_ComM_DoorRLStsInfo: accessed-variable=RTE_P_ComM_DoorRLStsInfo.tec_ComM_DoorRLStsInfo
              SEND_RTE_P_ComM_DoorRRStsInfo_tec_ComM_DoorRRStsInfo: accessed-variable=RTE_P_ComM_DoorRRStsInfo.tec_ComM_DoorRRStsInfo
              SEND_RTE_P_ComM_DrvrWarnLampStsInfo_tec_ComM_DrvrWarnLampStsInfo: accessed-variable=RTE_P_ComM_DrvrWarnLampStsInfo.tec_ComM_DrvrWarnLampStsInfo
              SEND_RTE_P_ComM_IBSCddActvInfo_tec_ComM_IBSCddActvInfo: accessed-variable=RTE_P_ComM_IBSCddActvInfo.tec_ComM_IBSCddActvInfo
              SEND_RTE_P_ComM_PassAirbStsInfo_tec_ComM_PassAirbStsInfo: accessed-variable=RTE_P_ComM_PassAirbStsInfo.tec_ComM_PassAirbStsInfo
              SEND_RTE_P_ComM_PassWarnLampStsInfo_tec_ComM_PassWarnLampStsInfo: accessed-variable=RTE_P_ComM_PassWarnLampStsInfo.tec_ComM_PassWarnLampStsInfo
              SEND_RTE_P_ComM_RollrBenchModInfo_tec_ComM_RollrBenchModInfo: accessed-variable=RTE_P_ComM_RollrBenchModInfo.tec_ComM_RollrBenchModInfo
              SEND_RTE_P_ComM_DCMFRMsgErrInfo_Bus_tec_ComM_DCMFRTimeoutInfo_Bus: accessed-variable=RTE_P_ComM_DCMFRMsgErrInfo_Bus.tec_ComM_DCMFRTimeoutInfo_Bus
              SEND_RTE_P_ComM_DCMRLMsgErrInfo_Bus_tec_ComM_DCMRLTimeoutInfo_Bus: accessed-variable=RTE_P_ComM_DCMRLMsgErrInfo_Bus.tec_ComM_DCMRLTimeoutInfo_Bus
              SEND_RTE_P_ComM_DCMRRMsgErrInfo_Bus_tec_ComM_DCMRRTimeoutInfo_Bus: accessed-variable=RTE_P_ComM_DCMRRMsgErrInfo_Bus.tec_ComM_DCMRRTimeoutInfo_Bus
              SEND_RTE_P_ComM_YRSAxSts_Flg_tec_ComM_YRSAxSts_Flg: accessed-variable=RTE_P_ComM_YRSAxSts.tec_ComM_YRSAxSts
              SEND_RTE_P_ComM_YRSAx_mps2q_tec_ComM_YRSAx_mps2q: accessed-variable=RTE_P_ComM_YRSAx_mps2q.tec_ComM_YRSAx_mps2q
              SEND_RTE_P_ComM_BMSSts02MsgErrInfo_Bus_tec_ComM_BMSSts02TimeoutDTCInfo_Bus: accessed-variable=RTE_P_ComM_BMSSts02MsgErrInfo_Bus.tec_ComM_BMSSts02TimeoutDTCInfo_Bus
              SEND_RTE_P_ComM_BMSSts02MsgErrInfo_Bus_tec_ComM_BMSSts02TimeoutInfo_Bus: accessed-variable=RTE_P_ComM_BMSSts02MsgErrInfo_Bus.tec_ComM_BMSSts02TimeoutInfo_Bus
              SEND_RTE_P_ComM_EBDFltStsInfo_tec_ComM_EBDFltStsInfo: accessed-variable=RTE_P_ComM_EBDFltStsInfo.tec_ComM_EBDFltStsInfo
              SEND_RTE_P_ComM_IBSSysStsInfo_tec_ComM_IBSSysStsInfo: accessed-variable=RTE_P_ComM_IBSSysStsInfo.tec_ComM_IBSSysStsInfo
              SEND_RTE_P_ComM_IBSTcsFltSts_Flg_tec_ComM_IBSTcsFltSts_Flg: accessed-variable=RTE_P_ComM_IBSTcsFltSts_Flg.tec_ComM_IBSTcsFltSts_Flg
              SEND_RTE_P_ComM_ACUYawRate_tec_ComM_ACUYawRate: accessed-variable=RTE_P_ComM_ACUYawRate.tec_ComM_ACUYawRate
              SEND_RTE_P_ComM_DCMFRMsgErrInfo_Bus_tec_ComM_DCMFRTimeoutIDTCnfo_Bus: accessed-variable=RTE_P_ComM_DCMFRMsgErrInfo_Bus.tec_ComM_DCMFRTimeoutDTCInfo_Bus
              SEND_RTE_P_ComM_DCMRLMsgErrInfo_Bus_tec_ComM_DCMRLTimeoutIDTCnfo_Bus: accessed-variable=RTE_P_ComM_DCMRLMsgErrInfo_Bus.tec_ComM_DCMRLTimeoutDTCInfo_Bus
              SEND_RTE_P_ComM_DCMRRMsgErrInfo_Bus_tec_ComM_DCMRRTimeoutIDTCnfo_Bus: accessed-variable=RTE_P_ComM_DCMRRMsgErrInfo_Bus.tec_ComM_DCMRRTimeoutDTCInfo_Bus
              SEND_RTE_P_ComM_IBSSts05MsgErrInfo_Bus_tec_ComM_IBSSts05CRCInfo_Bus: accessed-variable=RTE_P_ComM_IBSSts05MsgErrInfo_Bus.tec_ComM_IBSSts05CRCInfo_Bus
              SEND_RTE_P_ComM_IBSSts05MsgErrInfo_Bus_tec_ComM_IBSSts05E2ETimeoutInfo_Bus: accessed-variable=RTE_P_ComM_IBSSts05MsgErrInfo_Bus.tec_ComM_IBSSts05E2ETimeoutInfo_Bus
              SEND_RTE_P_ComM_ACUInfoMsgErrInfo_Bus_tec_ComM_ACUInfoCRCDTCInfo_Bus: accessed-variable=RTE_P_ComM_ACUInfoMsgErrInfo_Bus.tec_ComM_ACUInfoCRCDTCInfo_Bus
              SEND_RTE_P_ComM_ACUInfoUpdate_tec_ComM_ACUInfoUpdate: accessed-variable=RTE_P_ComM_ACUInfoUpdate.tec_ComM_ACUInfoUpdate
              SEND_RTE_P_ComM_ADCUAEB01MsgErrInfo_Bus_tec_ComM_ADCUAEB01CRCDTCInfo_Bus: accessed-variable=RTE_P_ComM_ADCUAEB01MsgErrInfo_Bus.tec_ComM_ADCUAEB01CRCDTCInfo_Bus
              SEND_RTE_P_ComM_ADCUAEB01MsgErrInfo_Bus_tec_ComM_ADCUAEB01TimeoutDTCInfo_Bus: accessed-variable=RTE_P_ComM_ADCUAEB01MsgErrInfo_Bus.tec_ComM_ADCUAEB01TimeoutDTCInfo_Bus
              SEND_RTE_P_ComM_ADCUAEBSt_tec_ComM_ADCUAEBSt: accessed-variable=RTE_P_ComM_ADCUAEBSt.tec_ComM_ADCUAEBSt
              SEND_RTE_P_ComM_ADCUAPS01MsgErrInfo_Bus_tec_ComM_ADCUAPS01CRCDTCInfo_Bus: accessed-variable=RTE_P_ComM_ADCUAPS01MsgErrInfo_Bus.tec_ComM_ADCUAPS01CRCDTCInfo_Bus
              SEND_RTE_P_ComM_ADCUAPS01MsgErrInfo_Bus_tec_ComM_ADCUAPS01TimeoutDTCInfo_Bus: accessed-variable=RTE_P_ComM_ADCUAPS01MsgErrInfo_Bus.tec_ComM_ADCUAPS01TimeoutDTCInfo_Bus
              SEND_RTE_P_ComM_ADCUPrkMod_tec_ComM_ADCUPrkMod: accessed-variable=RTE_P_ComM_ADCUPrkMod.tec_ComM_ADCUPrkMod
              SEND_RTE_P_ComM_BMSSts01Update_tec_ComM_BMSSts01Update: accessed-variable=RTE_P_ComM_BMSSts01Update.tec_ComM_BMSSts01Update
              SEND_RTE_P_ComM_IBSAPSMsgErrInfo_Bus_tec_ComM_IBSAPSCRCDTCInfo_Bus: accessed-variable=RTE_P_ComM_IBSAPSMsgErrInfo_Bus.tec_ComM_IBSAPSCRCDTCInfo_Bus
              SEND_RTE_P_ComM_IBSAPSMsgErrInfo_Bus_tec_ComM_IBSAPSTimeoutDTCInfo_Bus: accessed-variable=RTE_P_ComM_IBSAPSMsgErrInfo_Bus.tec_ComM_IBSAPSTimeoutDTCInfo_Bus
              SEND_RTE_P_ComM_IBSEPBControllerSts_tec_ComM_IBSEPBControllerSts: accessed-variable=RTE_P_ComM_IBSEPBControllerSts.tec_ComM_IBSEPBControllerSts
              SEND_RTE_P_ComM_IBSSUBEPBControllerSts_tec_ComM_IBSSUBEPBControllerSts: accessed-variable=RTE_P_ComM_IBSSUBEPBControllerSts.tec_ComM_IBSSUBEPBControllerSts
              SEND_RTE_P_ComM_IBSSUBEPBWrkSts_tec_ComM_IBSSUBEPBWrkSts: accessed-variable=RTE_P_ComM_IBSSUBEPBWrkSts.tec_ComM_IBSSUBEPBWrkSts
              SEND_RTE_P_ComM_IBSSts04MsgErrInfo_Bus_tec_ComM_IBSSts04CRCDTCInfo_Bus: accessed-variable=RTE_P_ComM_IBSSts04MsgErrInfo_Bus.tec_ComM_IBSSts04CRCDTCInfo_Bus
              SEND_RTE_P_ComM_IBSSts04MsgErrInfo_Bus_tec_ComM_IBSSts04CRCInfo_Bus: accessed-variable=RTE_P_ComM_IBSSts04MsgErrInfo_Bus.tec_ComM_IBSSts04CRCInfo_Bus
              SEND_RTE_P_ComM_IBSSts04MsgErrInfo_Bus_tec_ComM_IBSSts04E2ETimeoutInfo_Bus: accessed-variable=RTE_P_ComM_IBSSts04MsgErrInfo_Bus.tec_ComM_IBSSts04E2ETimeoutInfo_Bus
              SEND_RTE_P_ComM_IBSSts04MsgErrInfo_Bus_tec_ComM_IBSSts04TimeoutDTCInfo_Bus: accessed-variable=RTE_P_ComM_IBSSts04MsgErrInfo_Bus.tec_ComM_IBSSts04TimeoutDTCInfo_Bus
              SEND_RTE_P_ComM_SGW17MsgErrInfo_Bus_tec_ComM_SGW17TimeoutDTCInfo_Bus: accessed-variable=RTE_P_ComM_SGW17MsgErrInfo_Bus.tec_ComM_SGW17TimeoutDTCInfo_Bus
              SEND_RTE_P_ComM_SGW17MsgErrInfo_Bus_tec_ComM_SGW17TimeoutInfo_Bus: accessed-variable=RTE_P_ComM_SGW17MsgErrInfo_Bus.tec_ComM_SGW17TimeoutInfo_Bus
              SEND_RTE_P_ComM_SGWSysRdyReq_tec_ComM_SGWSysRdyReq: accessed-variable=RTE_P_ComM_SGWSysRdyReq.tec_ComM_SGWSysRdyReq
              SEND_RTE_P_ComM_IBSDtcFltSts_tec_ComM_IBSDtcFltSts: accessed-variable=RTE_P_ComM_IBSDtcFltSts.tec_ComM_IBSDtcFltSts
              SEND_RTE_P_ComM_SGWDchaSwtSts_tec_ComM_SGWDchaSwtSts: accessed-variable=RTE_P_ComM_SGWDchaSwtSts.tec_ComM_SGWDchaSwtSts
              SEND_RTE_P_ComM_IBSCdpActv_Flg_tec_ComM_IBSCdpActv_Flg: accessed-variable=RTE_P_ComM_IBSCdpActv_Flg.tec_ComM_IBSCdpActv_Flg
              SEND_RTE_P_ComM_IBSDtcActv_Flg_tec_ComM_IBSDtcActv_Flg: accessed-variable=RTE_P_ComM_IBSDtcActv_Flg.tec_ComM_IBSDtcActv_Flg
              SEND_RTE_P_ComM_IBSBrkStsVld_Flg_tec_ComM_IBSBrkStsVld_Flg: accessed-variable=RTE_P_ComM_IBSBrkStsVld_Flg.tec_ComM_IBSBrkStsVld_Flg
              SEND_RTE_P_ComM_IBSPlgrPrs_mm_tec_ComM_IBSPlgrPrs_mm: accessed-variable=RTE_P_ComM_IBSPlgrPrs_mm.tec_ComM_IBSPlgrPrs_mm
              SEND_RTE_P_ComM_ACU02MsgErrInfo_Bus_tec_ComM_ACU02TimeoutInfo_Bus: accessed-variable=RTE_P_ComM_ACU02MsgErrInfo_Bus.tec_ComM_ACU02TimeoutInfo_Bus
              SEND_RTE_P_ComM_IVIBuldChkStsInfo_tec_ComM_IVIBuldChkStsInfo: accessed-variable=RTE_P_ComM_IVIBuldChkStsInfo.tec_ComM_IVIBuldChkStsInfo
              SEND_RTE_P_ComM_WarnLampStsInfo_tec_ComM_WarnLampStsInfo: accessed-variable=RTE_P_ComM_WarnLampStsInfo.tec_ComM_WarnLampStsInfo
              SEND_RTE_P_ComM_EPSSteerGearAg_tec_ComM_EPSSteerGearAg: accessed-variable=RTE_P_ComM_EPSSteerGearAg.tec_ComM_EPSSteerGearAg
              SEND_RTE_P_ComM_EPSSteerGearAgVld_tec_ComM_EPSSteerGearAgVld: accessed-variable=RTE_P_ComM_EPSSteerGearAgVld.tec_ComM_EPSSteerGearAgVld
        R_CANHandlerInput_Cyclic_100ms
          data-receive-point-by-arguments:
            48 x access:
              REC_RTE_R_ComM_CGWPNC0_tec_ComM_CGWPNC0: accessed-variable=RTE_R_ComM_CGWPNC0.tec_ComM_CGWPNC0
              REC_RTE_R_ComM_CGWPNC1_tec_ComM_CGWPNC1: accessed-variable=RTE_R_ComM_CGWPNC1.tec_ComM_CGWPNC1
              REC_RTE_R_ComM_CGWPNC14_tec_ComM_CGWPNC14: accessed-variable=RTE_R_ComM_CGWPNC14.tec_ComM_CGWPNC14
              REC_RTE_R_ComM_CGWPNC17_tec_ComM_CGWPNC17: accessed-variable=RTE_R_ComM_CGWPNC17.tec_ComM_CGWPNC17
              REC_RTE_R_ComM_CGWPNC3_tec_ComM_CGWPNC3: accessed-variable=RTE_R_ComM_CGWPNC3.tec_ComM_CGWPNC3
              REC_RTE_R_ComM_VCUPNC1_tec_ComM_VCUPNC1: accessed-variable=RTE_R_ComM_VCUPNC1.tec_ComM_VCUPNC1
              REC_RTE_R_ComM_VCUPNC14_tec_ComM_VCUPNC14: accessed-variable=RTE_R_ComM_VCUPNC14.tec_ComM_VCUPNC14
              REC_RTE_R_ComM_VCUPNC17_tec_ComM_VCUPNC17: accessed-variable=RTE_R_ComM_VCUPNC17.tec_ComM_VCUPNC17
              REC_RTE_R_ComM_VCUPNC3_tec_ComM_VCUPNC3: accessed-variable=RTE_R_ComM_VCUPNC3.tec_ComM_VCUPNC3
              REC_RTE_R_ComM_CANBusOffInfo_Bus_tec_ComM_CHCANBusOffInfo_Bus: accessed-variable=RTE_R_ComM_CANBusOffInfo_Bus.tec_ComM_CHCANBusOffInfo_Bus
              REC_RTE_R_ComM_CANBusOffInfo_Bus_tec_ComM_EPTCANBusOffInfo_Bus: accessed-variable=RTE_R_ComM_CANBusOffInfo_Bus.tec_ComM_EPTCANBusOffInfo_Bus
              REC_RTE_R_DiagApp_DisableDCMReqInfo_tec_DiagApp_DisableDCMReqInfo: accessed-variable=RTE_R_DiagApp_DisableDCMReqInfo.tec_DiagApp_DisableDCMReqInfo
              REC_RTE_R_ComM_VCUPNC0_tec_ComM_VCUPNC0: accessed-variable=RTE_R_ComM_VCUPNC0.tec_ComM_VCUPNC0
              REC_RTE_R_DCChrMgmt_DcChrgStrt_Flg_tec_DCChrMgmt_DcChrgStrt_Flg: accessed-variable=RTE_R_DCChrMgmt_DcChrgStrt_Flg.tec_DCChrMgmt_DcChrgStrt_Flg
              REC_RTE_R_LvMgmt_BSBattUDcNorm_Flg_tec_LvMgmt_BSBattUDcNorm_Flg: accessed-variable=RTE_R_LvMgmt_BSBattUDcNorm_Flg.tec_LvMgmt_BSBattUDcNorm_Flg
              REC_RTE_R_LvMgmt_KL15ActSts_Flg_tec_LvMgmt_KL15ActSts_Flg: accessed-variable=RTE_R_LvMgmt_KL15ActSts_Flg.tec_LvMgmt_KL15ActSts_Flg
              REC_RTE_R_ComM_CGWPNC13_tec_ComM_CGWPNC13: accessed-variable=RTE_R_ComM_CGWPNC13.tec_ComM_CGWPNC13
              REC_RTE_R_ComM_VCUPNC13_tec_ComM_VCUPNC13: accessed-variable=RTE_R_ComM_VCUPNC13.tec_ComM_VCUPNC13
              REC_SG_ADCU_APS_02_SigGroup_SG_ADCU_APS_02_SigGroup: accessed-variable=SG_ADCU_APS_02_SigGroup.SG_ADCU_APS_02_SigGroup
              REC_SG_ADCU_DA_SigGroup_SG_ADCU_DA_SigGroup: accessed-variable=SG_ADCU_DA_SigGroup.SG_ADCU_DA_SigGroup
              REC_SG_APTC_TCU_SigGroup_SG_APTC_TCU_SigGroup: accessed-variable=SG_APTC_TCU_SigGroup.SG_APTC_TCU_SigGroup
              REC_SG_BMS_Charge_01_SigGroup_SG_BMS_Charge_01_SigGroup: accessed-variable=SG_BMS_Charge_01_SigGroup.SG_BMS_Charge_01_SigGroup
              REC_SG_BMS_Charge_02_SigGroup_SG_BMS_Charge_02_SigGroup: accessed-variable=SG_BMS_Charge_02_SigGroup.SG_BMS_Charge_02_SigGroup
              REC_SG_BMS_DIRelayState_SigGroup_SG_BMS_DIRelayState_SigGroup: accessed-variable=SG_BMS_DIRelayState_SigGroup.SG_BMS_DIRelayState_SigGroup
              REC_SG_BMS_status_03_SigGroup_SG_BMS_status_03_SigGroup: accessed-variable=SG_BMS_status_03_SigGroup.SG_BMS_status_03_SigGroup
              REC_SG_CGW_01_SigGroup_SG_CGW_01_SigGroup: accessed-variable=SG_CGW_01_SigGroup.SG_CGW_01_SigGroup
              REC_SG_DCM_FR_02_SigGroup_SG_DCM_FR_02_SigGroup: accessed-variable=SG_DCM_FR_02_SigGroup.SG_DCM_FR_02_SigGroup
              REC_SG_EVCOM_State_01_SigGroup_SG_EVCOM_State_01_SigGroup: accessed-variable=SG_EVCOM_State_01_SigGroup.SG_EVCOM_State_01_SigGroup
              REC_SG_MCU_DeratingStatus_SigGroup_SG_MCU_DeratingStatus_SigGroup: accessed-variable=SG_MCU_DeratingStatus_SigGroup.SG_MCU_DeratingStatus_SigGroup
              REC_SG_MCU_FailureCode_SigGroup_SG_MCU_FailureCode_SigGroup: accessed-variable=SG_MCU_FailureCode_SigGroup.SG_MCU_FailureCode_SigGroup
              REC_SG_POD_DCDC_01_SigGroup_SG_POD_DCDC_01_SigGroup: accessed-variable=SG_POD_DCDC_01_SigGroup.SG_POD_DCDC_01_SigGroup
              REC_SG_POD_OBC_CHRGSTATION_SigGroup_SG_POD_OBC_CHRGSTATION_SigGroup: accessed-variable=SG_POD_OBC_CHRGSTATION_SigGroup.SG_POD_OBC_CHRGSTATION_SigGroup
              REC_SG_POD_OBC_STATUS_02_SigGroup_SG_POD_OBC_STATUS_02_SigGroup: accessed-variable=SG_POD_OBC_STATUS_02_SigGroup.SG_POD_OBC_STATUS_02_SigGroup
              REC_SG_POD_OBC_STATUS_04_SigGroup_SG_POD_OBC_STATUS_04_SigGroup: accessed-variable=SG_POD_OBC_STATUS_04_SigGroup.SG_POD_OBC_STATUS_04_SigGroup
              REC_SG_POD_Status_01_SigGroup_SG_POD_Status_01_SigGroup: accessed-variable=SG_POD_Status_01_SigGroup.SG_POD_Status_01_SigGroup
              REC_SG_POD_Status_02_SigGroup_SG_POD_Status_02_SigGroup: accessed-variable=SG_POD_Status_02_SigGroup.SG_POD_Status_02_SigGroup
              REC_SG_SGW_16_SigGroup_SG_SGW_16_SigGroup: accessed-variable=SG_SGW_16_SigGroup.SG_SGW_16_SigGroup
              REC_SG_SGW_Time_SigGroup_SG_SGW_Time_SigGroup: accessed-variable=SG_SGW_Time_SigGroup.SG_SGW_Time_SigGroup
              REC_SG_TCU_01_SigGroup_SG_TCU_01_SigGroup: accessed-variable=SG_TCU_01_SigGroup.SG_TCU_01_SigGroup
              REC_SG_TCU_02_SigGroup_SG_TCU_02_SigGroup: accessed-variable=SG_TCU_02_SigGroup.SG_TCU_02_SigGroup
              REC_SG_BCM_06_SigGroup_SG_BCM_06_SigGroup: accessed-variable=SG_BCM_06_SigGroup.SG_BCM_06_SigGroup
              REC_SG_BMS_CellTemp_SigGroup_SG_BMS_CellTemp_SigGroup: accessed-variable=SG_BMS_CellTemp_SigGroup.SG_BMS_CellTemp_SigGroup
              REC_SG_BMS_CellVoltage_SigGroup_SG_BMS_CellVoltage_SigGroup: accessed-variable=SG_BMS_CellVoltage_SigGroup.SG_BMS_CellVoltage_SigGroup
              REC_SG_DCM_FL_02_SigGroup_SG_DCM_FL_02_SigGroup: accessed-variable=SG_DCM_FL_02_SigGroup.SG_DCM_FL_02_SigGroup
              REC_SG_SGW_01_SigGroup_SG_SGW_01_SigGroup: accessed-variable=SG_SGW_01_SigGroup.SG_SGW_01_SigGroup
              REC_SG_BMS_status_04_SigGroup_SG_BMS_status_04_SigGroup: accessed-variable=SG_BMS_status_04_SigGroup.SG_BMS_status_04_SigGroup
              REC_RTE_R_SecOC_BCM_Immo_State_YDF_BCM_Immo_State_YDF: accessed-variable=RTE_R_SecOC_BCM_Immo_State_YDF.BCM_Immo_State_YDF
              REC_SG_CGW_02_SigGroup_SG_CGW_02_SigGroup: accessed-variable=SG_CGW_02_SigGroup.SG_CGW_02_SigGroup
          data-send-points:
            110 x access:
              SEND_RTE_P_ComM_ADCUBodyReqMsgErrInfo_Bus_tec_ComM_ADCUBodyReqCRCDTCInfo_Bus: accessed-variable=RTE_P_ComM_ADCUBodyReqMsgErrInfo_Bus.tec_ComM_ADCUBodyReqCRCDTCInfo_Bus
              SEND_RTE_P_ComM_ADCUBodyReqMsgErrInfo_Bus_tec_ComM_ADCUBodyReqTimeoutDTCInfo_Bus: accessed-variable=RTE_P_ComM_ADCUBodyReqMsgErrInfo_Bus.tec_ComM_ADCUBodyReqTimeoutDTCInfo_Bus
              SEND_RTE_P_ComM_APTCTCUMsgErrInfo_Bus_tec_ComM_APTCTCUTimeoutDTCInfo_Bus: accessed-variable=RTE_P_ComM_APTCTCUMsgErrInfo_Bus.tec_ComM_APTCTCUTimeoutDTCInfo_Bus
              SEND_RTE_P_ComM_APTCTCUMsgErrInfo_Bus_tec_ComM_APTCTCUTimeoutInfo_Bus: accessed-variable=RTE_P_ComM_APTCTCUMsgErrInfo_Bus.tec_ComM_APTCTCUTimeoutInfo_Bus
              SEND_RTE_P_ComM_BCM06MsgErrInfo_Bus_tec_ComM_BCM06CRCDTCInfo_Bus: accessed-variable=RTE_P_ComM_BCM06MsgErrInfo_Bus.tec_ComM_BCM06CRCDTCInfo_Bus
              SEND_RTE_P_ComM_BCM06MsgErrInfo_Bus_tec_ComM_BCM06TimeoutDTCInfo_Bus: accessed-variable=RTE_P_ComM_BCM06MsgErrInfo_Bus.tec_ComM_BCM06TimeoutDTCInfo_Bus
              SEND_RTE_P_ComM_BCM06MsgErrInfo_Bus_tec_ComM_BCM06TimeoutInfo_Bus: accessed-variable=RTE_P_ComM_BCM06MsgErrInfo_Bus.tec_ComM_BCM06TimeoutInfo_Bus
              SEND_RTE_P_ComM_DCMFL02MsgErrInfo_Bus_tec_ComM_DCMFL02CRCDTCInfo_Bus: accessed-variable=RTE_P_ComM_DCMFL02MsgErrInfo_Bus.tec_ComM_DCMFL02CRCDTCInfo_Bus
              SEND_RTE_P_ComM_DCMFL02MsgErrInfo_Bus_tec_ComM_DCMFL02TimeoutDTCInfo_Bus: accessed-variable=RTE_P_ComM_DCMFL02MsgErrInfo_Bus.tec_ComM_DCMFL02TimeoutDTCInfo_Bus
              SEND_RTE_P_ComM_DCMFL02MsgErrInfo_Bus_tec_ComM_DCMFL02TimeoutInfo_Bus: accessed-variable=RTE_P_ComM_DCMFL02MsgErrInfo_Bus.tec_ComM_DCMFL02TimeoutInfo_Bus
              SEND_RTE_P_ComM_CGW01MsgErrInfo_Bus_tec_ComM_CGW01TimeoutDTCInfo_Bus: accessed-variable=RTE_P_ComM_CGW01MsgErrInfo_Bus.tec_ComM_CGW01TimeoutDTCInfo_Bus
              SEND_RTE_P_ComM_CGW01MsgErrInfo_Bus_tec_ComM_CGW01TimeoutInfo_Bus: accessed-variable=RTE_P_ComM_CGW01MsgErrInfo_Bus.tec_ComM_CGW01TimeoutInfo_Bus
              SEND_RTE_P_ComM_EVCOMSts01MsgErrInfo_Bus_tec_ComM_EVCOMSts01TimeoutDTCInfo_Bus: accessed-variable=RTE_P_ComM_EVCOMSts01MsgErrInfo_Bus.tec_ComM_EVCOMSts01TimeoutDTCInfo_Bus
              SEND_RTE_P_ComM_EVCOMSts01MsgErrInfo_Bus_tec_ComM_EVCOMSts01TimeoutInfo_Bus: accessed-variable=RTE_P_ComM_EVCOMSts01MsgErrInfo_Bus.tec_ComM_EVCOMSts01TimeoutInfo_Bus
              SEND_RTE_P_ComM_MCUFailrCodMsgErrInfo_Bus_tec_ComM_MCUFailrCodCRCDTCInfo_Bus: accessed-variable=RTE_P_ComM_MCUFailrCodMsgErrInfo_Bus.tec_ComM_MCUFailrCodCRCDTCInfo_Bus
              SEND_RTE_P_ComM_MCUFailrCodMsgErrInfo_Bus_tec_ComM_MCUFailrCodCRCInfo_Bus: accessed-variable=RTE_P_ComM_MCUFailrCodMsgErrInfo_Bus.tec_ComM_MCUFailrCodCRCInfo_Bus
              SEND_RTE_P_ComM_MCUFailrCodMsgErrInfo_Bus_tec_ComM_MCUFailrCodE2ETimeoutInfo_Bus: accessed-variable=RTE_P_ComM_MCUFailrCodMsgErrInfo_Bus.tec_ComM_MCUFailrCodE2ETimeoutInfo_Bus
              SEND_RTE_P_ComM_MCUFailrCodMsgErrInfo_Bus_tec_ComM_MCUFailrCodTimeoutDTCInfo_Bus: accessed-variable=RTE_P_ComM_MCUFailrCodMsgErrInfo_Bus.tec_ComM_MCUFailrCodTimeoutDTCInfo_Bus
              SEND_RTE_P_ComM_PODDCDC01MsgErrInfo_Bus_tec_ComM_PODDCDC01TimeoutDTCInfo_Bus: accessed-variable=RTE_P_ComM_PODDCDC01MsgErrInfo_Bus.tec_ComM_PODDCDC01TimeoutDTCInfo_Bus
              SEND_RTE_P_ComM_PODDCDC01MsgErrInfo_Bus_tec_ComM_PODDCDC01TimeoutInfo_Bus: accessed-variable=RTE_P_ComM_PODDCDC01MsgErrInfo_Bus.tec_ComM_PODDCDC01TimeoutInfo_Bus
              SEND_RTE_P_ComM_PODOBCChrgStatMsgErrInfo_Bus_tec_ComM_PODOBCChrgStatTimeoutDTCInfo_Bus: accessed-variable=RTE_P_ComM_PODOBCChrgStatMsgErrInfo_Bus.tec_ComM_PODOBCChrgStatTimeoutDTCInfo_Bus
              SEND_RTE_P_ComM_PODOBCChrgStatMsgErrInfo_Bus_tec_ComM_PODOBCChrgStatTimeoutInfo_Bus: accessed-variable=RTE_P_ComM_PODOBCChrgStatMsgErrInfo_Bus.tec_ComM_PODOBCChrgStatTimeoutInfo_Bus
              SEND_RTE_P_ComM_PODSts01TimeoutInfo_Bus_tec_ComM_PODSts01TimeoutInfo_Bus: accessed-variable=RTE_P_ComM_PODSts01TimeoutInfo_Bus.tec_ComM_PODSts01TimeoutInfo_Bus
              SEND_RTE_P_ComM_SGWTimMsgErrInfo_Bus_tec_ComM_SGWTimTimeoutDTCInfo_Bus: accessed-variable=RTE_P_ComM_SGWTimMsgErrInfo_Bus.tec_ComM_SGWTimTimeoutDTCInfo_Bus
              SEND_RTE_P_ComM_SGWTimMsgErrInfo_Bus_tec_ComM_SGWTimTimeoutInfo_Bus: accessed-variable=RTE_P_ComM_SGWTimMsgErrInfo_Bus.tec_ComM_SGWTimTimeoutInfo_Bus
              SEND_RTE_P_ComM_TCU01MsgErrInfo_Bus_tec_ComM_TCU01TimeoutDTCInfo_Bus: accessed-variable=RTE_P_ComM_TCU01MsgErrInfo_Bus.tec_ComM_TCU01TimeoutDTCInfo_Bus
              SEND_RTE_P_ComM_TCU01MsgErrInfo_Bus_tec_ComM_TCU01TimeoutInfo_Bus: accessed-variable=RTE_P_ComM_TCU01MsgErrInfo_Bus.tec_ComM_TCU01TimeoutInfo_Bus
              SEND_RTE_P_ComM_OBCLostSpcInfo_tec_ComM_OBCLostSpcInfo: accessed-variable=RTE_P_ComM_OBCLostSpcInfo.tec_ComM_OBCLostSpcInfo
              SEND_RTE_P_ComM_BMSBattDispSOC_pct_tec_ComM_BMSBattDispSOC_pct: accessed-variable=RTE_P_ComM_BMSBattDispSOC_pct.tec_ComM_BMSBattDispSOC_pct
              SEND_RTE_P_ComM_BMSBattPckUDc_V_tec_ComM_BMSBattPckUDc_V: accessed-variable=RTE_P_ComM_BMSBattPckUDc_V.tec_ComM_BMSBattPckUDc_V
              SEND_RTE_P_ComM_BMSNegRlySts_Enum_tec_ComM_BMSNegRlySts_Enum: accessed-variable=RTE_P_ComM_BMSNegRlySts_Enum.tec_ComM_BMSNegRlySts_Enum
              SEND_RTE_P_ComM_BMSPosRlySts_Enum_tec_ComM_BMSPosRlySts_Enum: accessed-variable=RTE_P_ComM_BMSPosRlySts_Enum.tec_ComM_BMSPosRlySts_Enum
              SEND_RTE_P_ComM_DCDCHvInpIDc_A_tec_ComM_DCDCHvInpIDc_A: accessed-variable=RTE_P_ComM_DCDCHvInpIDc_A.tec_ComM_DCDCHvInpIDc_A
              SEND_RTE_P_ComM_DCDCHvInpUDc_V_tec_ComM_DCDCHvInpUDc_V: accessed-variable=RTE_P_ComM_DCDCHvInpUDc_V.tec_ComM_DCDCHvInpUDc_V
              SEND_RTE_P_ComM_DCDCWrkMod_Enum_tec_ComM_DCDCWrkMod_Enum: accessed-variable=RTE_P_ComM_DCDCWrkMod_Enum.tec_ComM_DCDCWrkMod_Enum
              SEND_RTE_P_ComM_MotMaxTq_Nm_tec_ComM_MotMaxTq_Nm: accessed-variable=RTE_P_ComM_MotMaxTq_Nm.tec_ComM_MotMaxTq_Nm
              SEND_RTE_P_ComM_MotMinTq_Nm_tec_ComM_MotMinTq_Nm: accessed-variable=RTE_P_ComM_MotMinTq_Nm.tec_ComM_MotMinTq_Nm
              SEND_RTE_P_ComM_BMSBattDchaIDc_A_tec_ComM_BMSBattDchaIDc_A: accessed-variable=RTE_P_ComM_BMSBattDchaIDc_A.tec_ComM_BMSBattDchaIDc_A
              SEND_RTE_P_ComM_BMSBattFbIDc_A_tec_ComM_BMSBattFbIDc_A: accessed-variable=RTE_P_ComM_BMSBattFbIDc_A.tec_ComM_BMSBattFbIDc_A
              SEND_RTE_P_ComM_HVCHIDc_A_tec_ComM_HVCHIDc_A: accessed-variable=RTE_P_ComM_HVCHIDc_A.tec_ComM_HVCHIDc_A
              SEND_RTE_P_ComM_HVCHUDc_V_tec_ComM_HVCHUDc_V: accessed-variable=RTE_P_ComM_HVCHUDc_V.tec_ComM_HVCHUDc_V
              SEND_RTE_P_ComM_OBCCCSts_Enum_tec_ComM_OBCCCSts_Enum: accessed-variable=RTE_P_ComM_OBCCCSts_Enum.tec_ComM_OBCCCSts_Enum
              SEND_RTE_P_ComM_OBCChrgSts_Enum_tec_ComM_OBCChrgSts_Enum: accessed-variable=RTE_P_ComM_OBCChrgSts_Enum.tec_ComM_OBCChrgSts_Enum
              SEND_RTE_P_ComM_TMSTotPwrReq_W_tec_ComM_TMSTotPwrReq_W: accessed-variable=RTE_P_ComM_TMSTotPwrReq_W.tec_ComM_TMSTotPwrReq_W
              SEND_RTE_P_ComM_AbortErrUDc_Enum_tec_ComM_AbortErrUDc_Enum: accessed-variable=RTE_P_ComM_AbortErrUDc_Enum.tec_ComM_AbortErrUDc_Enum
              SEND_RTE_P_ComM_AbortFltBattTemp_Enum_tec_ComM_AbortFltBattTemp_Enum: accessed-variable=RTE_P_ComM_AbortFltBattTemp_Enum.tec_ComM_AbortFltBattTemp_Enum
              SEND_RTE_P_ComM_AbortFltBMSTemp_Enum_tec_ComM_AbortFltBMSTemp_Enum: accessed-variable=RTE_P_ComM_AbortFltBMSTemp_Enum.tec_ComM_AbortFltBMSTemp_Enum
              SEND_RTE_P_ComM_AcChrgPha_Enum_tec_ComM_AcChrgPha_Enum: accessed-variable=RTE_P_ComM_AcChrgPha_Enum.tec_ComM_AcChrgPha_Enum
              SEND_RTE_P_ComM_APTCPwrCns_Kw_tec_ComM_APTCPwrCns_Kw: accessed-variable=RTE_P_ComM_APTCPwrCns_Kw.tec_ComM_APTCPwrCns_Kw
              SEND_RTE_P_ComM_BattChrgnModReq_Enum_tec_ComM_BattChrgnModReq_Enum: accessed-variable=RTE_P_ComM_BattChrgnModReq_Enum.tec_ComM_BattChrgnModReq_Enum
              SEND_RTE_P_ComM_BattMaxTemp_C_tec_ComM_BMSBattMaxTemp_C: accessed-variable=RTE_P_ComM_BattMaxTemp_C.tec_ComM_BMSBattMaxTemp_C
              SEND_RTE_P_ComM_BattMinTemp_C_tec_ComM_BMSBattMinTemp_C: accessed-variable=RTE_P_ComM_BattMinTemp_C.tec_ComM_BMSBattMinTemp_C
              SEND_RTE_P_ComM_BMSBattAllowChrgIDc_A_tec_ComM_BMSBattAllowChrgIDc_A: accessed-variable=RTE_P_ComM_BMSBattAllowChrgIDc_A.tec_ComM_BMSBattAllowChrgIDc_A
              SEND_RTE_P_ComM_BMSBattLnkUDc_V_tec_ComM_BMSBattLnkUDc_V: accessed-variable=RTE_P_ComM_BMSBattLnkUDc_V.tec_ComM_BMSBattLnkUDc_V
              SEND_RTE_P_ComM_BMSBattMaxChrgnUDc_V_tec_ComM_BMSBattMaxChrgnUDc_V: accessed-variable=RTE_P_ComM_BMSBattMaxChrgnUDc_V.tec_ComM_BMSBattMaxChrgnUDc_V
              SEND_RTE_P_ComM_BMSChrgCmplSts_Enum_tec_ComM_BMSChrgCmplSts_Enum: accessed-variable=RTE_P_ComM_BMSChrgCmplSts_Enum.tec_ComM_BMSChrgCmplSts_Enum
              SEND_RTE_P_ComM_BMSChrgReqSts_Enum_tec_ComM_BMSChrgReqSts_Enum: accessed-variable=RTE_P_ComM_BMSChrgReqSts_Enum.tec_ComM_BMSChrgReqSts_Enum
              SEND_RTE_P_ComM_BMSPTCUDc_V_tec_ComM_BMSPTCUDc_V: accessed-variable=RTE_P_ComM_BMSPTCUDc_V.tec_ComM_BMSPTCUDc_V
              SEND_RTE_P_ComM_BMSRemnChrgTim_min_tec_ComM_BMSRemnChrgTim_min: accessed-variable=RTE_P_ComM_BMSRemnChrgTim_min.tec_ComM_BMSRemnChrgTim_min
              SEND_RTE_P_ComM_ChrgnRchSetVal_Enum_tec_ComM_ChrgnRchSetVal_Enum: accessed-variable=RTE_P_ComM_ChrgnRchSetVal_Enum.tec_ComM_ChrgnRchSetVal_Enum
              SEND_RTE_P_ComM_ChrgnRchTarCellUDc_Enum_tec_ComM_ChrgnRchTarCellUDc_Enum: accessed-variable=RTE_P_ComM_ChrgnRchTarCellUDc_Enum.tec_ComM_ChrgnRchTarCellUDc_Enum
              SEND_RTE_P_ComM_ChrgnRchTarTotUDc_Enum_tec_ComM_ChrgnRchTarTotUDc_Enum: accessed-variable=RTE_P_ComM_ChrgnRchTarTotUDc_Enum.tec_ComM_ChrgnRchTarTotUDc_Enum
              SEND_RTE_P_ComM_DcInletASnsrSts_Enum_tec_ComM_DcInletASnsrSts_Enum: accessed-variable=RTE_P_ComM_DcInletASnsrSts_Enum.tec_ComM_DcInletASnsrSts_Enum
              SEND_RTE_P_ComM_DcInletATemp_C_tec_ComM_DcInletATemp_C: accessed-variable=RTE_P_ComM_DcInletATemp_C.tec_ComM_DcInletATemp_C
              SEND_RTE_P_ComM_DcInletBSnsrSts_Enum_tec_ComM_DcInletBSnsrSts_Enum: accessed-variable=RTE_P_ComM_DcInletBSnsrSts_Enum.tec_ComM_DcInletBSnsrSts_Enum
              SEND_RTE_P_ComM_DcInletBTemp_C_tec_ComM_DcInletBTemp_C: accessed-variable=RTE_P_ComM_DcInletBTemp_C.tec_ComM_DcInletBTemp_C
              SEND_RTE_P_ComM_ElectcLockSts_Enum_tec_ComM_ElectcLockSts_Enum: accessed-variable=RTE_P_ComM_ElectcLockSts_Enum.tec_ComM_ElectcLockSts_Enum
              SEND_RTE_P_ComM_EVCOMActPwrCns_Kw_tec_ComM_EVCOMActPwrCns_Kw: accessed-variable=RTE_P_ComM_EVCOMActPwrCns_Kw.tec_ComM_EVCOMActPwrCns_Kw
              SEND_RTE_P_ComM_OBCCCIDcLmt_A_tec_ComM_OBCCCIDcLmt_A: accessed-variable=RTE_P_ComM_OBCCCIDcLmt_A.tec_ComM_OBCCCIDcLmt_A
              SEND_RTE_P_ComM_OBCCPIDcLmt_A_tec_ComM_OBCCPIDcLmt_A: accessed-variable=RTE_P_ComM_OBCCPIDcLmt_A.tec_ComM_OBCCPIDcLmt_A
              SEND_RTE_P_ComM_OBCCPPwmDuty_pct_tec_ComM_OBCCPPwmDuty_pct: accessed-variable=RTE_P_ComM_OBCCPPwmDuty_pct.tec_ComM_OBCCPPwmDuty_pct
              SEND_RTE_P_ComM_OBCCPSts_Enum_tec_ComM_OBCCPSts_Enum: accessed-variable=RTE_P_ComM_OBCCPSts_Enum.tec_ComM_OBCCPSts_Enum
              SEND_RTE_P_ComM_OBCInpIAc_A_tec_ComM_OBCInpIAc_A: accessed-variable=RTE_P_ComM_OBCInpIAc_A.tec_ComM_OBCInpIAc_A
              SEND_RTE_P_ComM_OBCInpUAc_V_tec_ComM_OBCInpUAc_V: accessed-variable=RTE_P_ComM_OBCInpUAc_V.tec_ComM_OBCInpUAc_V
              SEND_RTE_P_ComM_OBCMaxAllwdIDc_A_tec_ComM_OBCMaxAllwdIDc_A: accessed-variable=RTE_P_ComM_OBCMaxAllwdIDc_A.tec_ComM_OBCMaxAllwdIDc_A
              SEND_RTE_P_ComM_OBCOutpIDc_A_tec_ComM_OBCOutpIDc_A: accessed-variable=RTE_P_ComM_OBCOutpIDc_A.tec_ComM_OBCOutpIDc_A
              SEND_RTE_P_ComM_OBCOutpUDc_V_tec_ComM_OBCOutpUDc_V: accessed-variable=RTE_P_ComM_OBCOutpUDc_V.tec_ComM_OBCOutpUDc_V
              SEND_RTE_P_ComM_PEPSPwrMod_Enum_tec_ComM_PEPSPwrMod_Enum: accessed-variable=RTE_P_ComM_PEPSPwrMod_Enum.tec_ComM_PEPSPwrMod_Enum
              SEND_RTE_P_ComM_PODDCFCUDc_V_tec_ComM_PODDCFCUDc_V: accessed-variable=RTE_P_ComM_PODDCFCUDc_V.tec_ComM_PODDCFCUDc_V
              SEND_RTE_P_ComM_PODDcPosRlySts_Enum_tec_ComM_PODDcPosRlySts_Enum: accessed-variable=RTE_P_ComM_PODDcPosRlySts_Enum.tec_ComM_PODDcPosRlySts_Enum
              SEND_RTE_P_ComM_S2SwtSts_Enum_tec_ComM_S2SwtSts_Enum: accessed-variable=RTE_P_ComM_S2SwtSts_Enum.tec_ComM_S2SwtSts_Enum
              SEND_RTE_P_ComM_BCMImmoSts_Flg_tec_ComM_BCMImmoSts_Flg: accessed-variable=RTE_P_ComM_BCMImmoSts_Flg.tec_ComM_BCMImmoSts_Flg
              SEND_RTE_P_ComM_MCUErrLvl_Enum_tec_ComM_MCUErrLvl_Enum: accessed-variable=RTE_P_ComM_MCUErrLvl_Enum.tec_ComM_MCUErrLvl_Enum
              SEND_RTE_P_ComM_SGWRemHvCtrlReq_Enum_tec_ComM_SGWRemHvCtrlReq_Enum: accessed-variable=RTE_P_ComM_SGWRemHvCtrlReq_Enum.tec_ComM_SGWRemHvCtrlReq_Enum
              SEND_RTE_P_ComM_SGWTimeDayInfo_tec_ComM_SGWTimeDayInfo: accessed-variable=RTE_P_ComM_SGWTimeDayInfo.tec_ComM_SGWTimeDayInfo
              SEND_RTE_P_ComM_SGWTimeHourInfo_tec_ComM_SGWTimeHourInfo: accessed-variable=RTE_P_ComM_SGWTimeHourInfo.tec_ComM_SGWTimeHourInfo
              SEND_RTE_P_ComM_SGWTimeMinuteInfo_tec_ComM_SGWTimeMinuteInfo: accessed-variable=RTE_P_ComM_SGWTimeMinuteInfo.tec_ComM_SGWTimeMinuteInfo
              SEND_RTE_P_ComM_SGWTimeMonthInfo_tec_ComM_SGWTimeMonthInfo: accessed-variable=RTE_P_ComM_SGWTimeMonthInfo.tec_ComM_SGWTimeMonthInfo
              SEND_RTE_P_ComM_SGWTimeSecondInfo_tec_ComM_SGWTimeSecondInfo: accessed-variable=RTE_P_ComM_SGWTimeSecondInfo.tec_ComM_SGWTimeSecondInfo
              SEND_RTE_P_ComM_SGWTimeYearInfo_tec_ComM_SGWTimeYearInfo: accessed-variable=RTE_P_ComM_SGWTimeYearInfo.tec_ComM_SGWTimeYearInfo
              SEND_RTE_P_ComM_TCUErrLvl_Enum_tec_ComM_TCUErrLvl_Enum: accessed-variable=RTE_P_ComM_TCUErrLvl_Enum.tec_ComM_TCUErrLvl_Enum
              SEND_RTE_P_ComM_TCUHvPwrSts_Enum_tec_ComM_TCUHvPwrSts_Enum: accessed-variable=RTE_P_ComM_TCUHvPwrSts_Enum.tec_ComM_TCUHvPwrSts_Enum
              SEND_RTE_P_ComM_AbortErrIDc_Enum_tec_ComM_AbortErrIDc_Enum: accessed-variable=RTE_P_ComM_AbortErrIDc_Enum.tec_ComM_AbortErrIDc_Enum
              SEND_RTE_P_ComM_CGWVehStatusInfo_tec_ComM_CGWVehStatusInfo: accessed-variable=RTE_P_ComM_CGWVehStatusInfo.tec_ComM_CGWVehStatusInfo
              SEND_RTE_P_ComM_DoorFLStsInfo_tec_ComM_DoorFLStsInfo: accessed-variable=RTE_P_ComM_DoorFLStsInfo.tec_ComM_DoorFLStsInfo
              SEND_RTE_P_ComM_OBCChrgOutpPwrAvl_Kw_tec_ComM_OBCChrgOutpPwrAvl_Kw: accessed-variable=RTE_P_ComM_OBCChrgOutpPwrAvl_Kw.tec_ComM_OBCChrgOutpPwrAvl_Kw
              SEND_RTE_P_ComM_ADCUDAMod_tec_ComM_ADCUDAMod: accessed-variable=RTE_P_ComM_ADCUDAMod.tec_ComM_ADCUDAMod
              SEND_RTE_P_ComM_ADCURemPrkMod_tec_ComM_ADCURemPrkMod: accessed-variable=RTE_P_ComM_ADCURemPrkMod.tec_ComM_ADCURemPrkMod
              SEND_RTE_P_ComM_DCMAmbTemp_tec_ComM_DCMAmbTemp: accessed-variable=RTE_P_ComM_DCMAmbTemp.tec_ComM_DCMAmbTemp
              SEND_RTE_P_ComM_DCMAmbTempVld_tec_ComM_DCMAmbTempVld: accessed-variable=RTE_P_ComM_DCMAmbTempVld.tec_ComM_DCMAmbTempVld
              SEND_RTE_P_ComM_IVIVrState_tec_ComM_IVIVrState: accessed-variable=RTE_P_ComM_IVIVrState.tec_ComM_IVIVrState
              SEND_RTE_P_ComM_MCUFailCodeUpdate_tec_ComM_MCUFailCodeUpdate: accessed-variable=RTE_P_ComM_MCUFailCodeUpdate.tec_ComM_MCUFailCodeUpdate
              SEND_RTE_P_ComM_TCU01Update_tec_ComM_TCU01Update: accessed-variable=RTE_P_ComM_TCU01Update.tec_ComM_TCU01Update
              SEND_RTE_P_ComM_ADCUDAMsgErrInfo_Bus_tec_ComM_ADCUDACRCDTCInfo_Bus: accessed-variable=RTE_P_ComM_ADCUDAMsgErrInfo_Bus.tec_ComM_ADCUDACRCDTCInfo_Bus
              SEND_RTE_P_ComM_ADCUDAMsgErrInfo_Bus_tec_ComM_ADCUDATimeoutDTCInfo_Bus: accessed-variable=RTE_P_ComM_ADCUDAMsgErrInfo_Bus.tec_ComM_ADCUDATimeoutDTCInfo_Bus
              SEND_RTE_P_ComM_CGW01MsgErrInfo_Bus_tec_ComM_CGW01CRCDTCInfo_Bus: accessed-variable=RTE_P_ComM_CGW01MsgErrInfo_Bus.tec_ComM_CGW01CRCDTCInfo_Bus
              SEND_RTE_P_ComM_SGW16MsgErrInfo_Bus_tec_ComM_SGW16TimeoutDTCInfo_Bus: accessed-variable=RTE_P_ComM_SGW16MsgErrInfo_Bus.tec_ComM_SGW16TimeoutDTCInfo_Bus
              SEND_RTE_P_ComM_SGW16MsgErrInfo_Bus_tec_ComM_SGW16TimeoutInfo_Bus: accessed-variable=RTE_P_ComM_SGW16MsgErrInfo_Bus.tec_ComM_SGW16TimeoutInfo_Bus
              SEND_RTE_P_ComM_BMSPTCRlyStsInfo_tec_ComM_BMSPTCRlyStsInfo: accessed-variable=RTE_P_ComM_BMSPTCRlyStsInfo.tec_ComM_BMSPTCRlyStsInfo
              SEND_RTE_P_ComM_DCMFRAmbTempInfo_tec_ComM_DCMFRAmbTempInfo: accessed-variable=RTE_P_ComM_DCMFRAmbTempInfo.tec_ComM_DCMFRAmbTempInfo
        R_CANHandlerInput_Cyclic_200ms
          data-receive-point-by-arguments:
            16 x access:
              REC_RTE_R_DiagApp_DisableDCMReqInfo_tec_DiagApp_DisableDCMReqInfo: accessed-variable=RTE_R_DiagApp_DisableDCMReqInfo.tec_DiagApp_DisableDCMReqInfo
              REC_RTE_R_ComM_CANBusOffInfo_Bus_tec_ComM_CHCANBusOffInfo_Bus: accessed-variable=RTE_R_ComM_CANBusOffInfo_Bus.tec_ComM_CHCANBusOffInfo_Bus
              REC_RTE_R_ComM_CANBusOffInfo_Bus_tec_ComM_EPTCANBusOffInfo_Bus: accessed-variable=RTE_R_ComM_CANBusOffInfo_Bus.tec_ComM_EPTCANBusOffInfo_Bus
              REC_RTE_R_ComM_CGWPNC17_tec_ComM_CGWPNC17: accessed-variable=RTE_R_ComM_CGWPNC17.tec_ComM_CGWPNC17
              REC_RTE_R_ComM_VCUPNC17_tec_ComM_VCUPNC17: accessed-variable=RTE_R_ComM_VCUPNC17.tec_ComM_VCUPNC17
              REC_RTE_R_ComM_BSBatVltHlResInfo_tec_ComM_BSBatVltHlResInfo: accessed-variable=RTE_R_ComM_BSBatVltHlResInfo.tec_ComM_BSBatVltHlResInfo
              REC_RTE_R_ComM_BSBattSOC_pct_tec_ComM_BSBattSOC_pct: accessed-variable=RTE_R_ComM_BSBattSOC_pct.tec_ComM_BSBattSOC_pct
              REC_RTE_R_DCChrMgmt_DcChrgStrt_Flg_tec_DCChrMgmt_DcChrgStrt_Flg: accessed-variable=RTE_R_DCChrMgmt_DcChrgStrt_Flg.tec_DCChrMgmt_DcChrgStrt_Flg
              REC_RTE_R_LvMgmt_BSBattUDcNorm_Flg_tec_LvMgmt_BSBattUDcNorm_Flg: accessed-variable=RTE_R_LvMgmt_BSBattUDcNorm_Flg.tec_LvMgmt_BSBattUDcNorm_Flg
              REC_SG_BMS_ErrorInfo_SigGroup_SG_BMS_ErrorInfo_SigGroup: accessed-variable=SG_BMS_ErrorInfo_SigGroup.SG_BMS_ErrorInfo_SigGroup
              REC_SG_BMS_TCU_SigGroup_SG_BMS_TCU_SigGroup: accessed-variable=SG_BMS_TCU_SigGroup.SG_BMS_TCU_SigGroup
              REC_SG_CGW_02_SigGroup_SG_CGW_02_SigGroup: accessed-variable=SG_CGW_02_SigGroup.SG_CGW_02_SigGroup
              REC_SG_POD_DCDC_02_SigGroup_SG_POD_DCDC_02_SigGroup: accessed-variable=SG_POD_DCDC_02_SigGroup.SG_POD_DCDC_02_SigGroup
              REC_SG_POD_OBC_STATUS_03_SigGroup_SG_POD_OBC_STATUS_03_SigGroup: accessed-variable=SG_POD_OBC_STATUS_03_SigGroup.SG_POD_OBC_STATUS_03_SigGroup
              REC_SG_BCM_05_SigGroup_SG_BCM_05_SigGroup: accessed-variable=SG_BCM_05_SigGroup.SG_BCM_05_SigGroup
              REC_RTE_R_SecOC_BCM_Authentication_YDF_BCM_Authentication_YDF: accessed-variable=RTE_R_SecOC_BCM_Authentication_YDF.BCM_Authentication_YDF
          data-send-points:
            25 x access:
              SEND_RTE_P_ComM_BMSErrInfoTimeoutInfo_Bus_tec_ComM_BMSErrInfoTimeoutInfo_Bus: accessed-variable=RTE_P_ComM_BMSErrInfoTimeoutInfo_Bus.tec_ComM_BMSErrInfoTimeoutInfo_Bus
              SEND_RTE_P_ComM_BMSCellHiTempErr_Enum_tec_ComM_BMSCellHiTempErr_Enum: accessed-variable=RTE_P_ComM_BMSCellHiTempErr_Enum.tec_ComM_BMSCellHiTempErr_Enum
              SEND_RTE_P_ComM_BMSSOCErrHiSts_Enum_tec_ComM_BMSSOCHiErrSts_Enum: accessed-variable=RTE_P_ComM_BMSSOCErrHiSts_Enum.tec_ComM_BMSSOCHiErrSts_Enum
              SEND_RTE_P_ComM_BMSSOCErrLoSts_Enum_tec_ComM_BMSSOCLoErrSts_Enum: accessed-variable=RTE_P_ComM_BMSSOCErrLoSts_Enum.tec_ComM_BMSSOCLoErrSts_Enum
              SEND_RTE_P_ComM_ChrgnIDcErrSts_Enum_tec_ComM_ChrgnIDcErrSts_Enum: accessed-variable=RTE_P_ComM_ChrgnIDcErrSts_Enum.tec_ComM_ChrgnIDcErrSts_Enum
              SEND_RTE_P_ComM_FLSeatBltRmnReqInfo_tec_ComM_FLSeatBltRmnReqInfo: accessed-variable=RTE_P_ComM_FLSeatBltRmnReqInfo.tec_ComM_FLSeatBltRmnReqInfo
              SEND_RTE_P_ComM_FRSeatBltRmnReqInfo_tec_ComM_FRSeatBltRmnReqInfo: accessed-variable=RTE_P_ComM_FRSeatBltRmnReqInfo.tec_ComM_FRSeatBltRmnReqInfo
              SEND_RTE_P_ComM_MaxCellUDcErrSts_Enum_tec_ComM_MaxCellUDcErrSts_Enum: accessed-variable=RTE_P_ComM_MaxCellUDcErrSts_Enum.tec_ComM_MaxCellUDcErrSts_Enum
              SEND_RTE_P_ComM_MinCellUDcErrSts_Enum_tec_ComM_MinCellUDcErrSts_Enum: accessed-variable=RTE_P_ComM_MinCellUDcErrSts_Enum.tec_ComM_MinCellUDcErrSts_Enum
              SEND_RTE_P_ComM_OBCSide1OvrTempFlt_Flg_tec_ComM_OBCSide1OvrTempFlt_Flg: accessed-variable=RTE_P_ComM_OBCSide1OvrTempFlt_Flg.tec_ComM_OBCSide1OvrTempFlt_Flg
              SEND_RTE_P_ComM_RLSeatBltRmnReqInfo_tec_ComM_RLSeatBltRmnReqInfo: accessed-variable=RTE_P_ComM_RLSeatBltRmnReqInfo.tec_ComM_RLSeatBltRmnReqInfo
              SEND_RTE_P_ComM_RRSeatBltRmnReqInfo_tec_ComM_RRSeatBltRmnReqInfo: accessed-variable=RTE_P_ComM_RRSeatBltRmnReqInfo.tec_ComM_RRSeatBltRmnReqInfo
              SEND_RTE_P_ComM_BCMAntithftSts_Enum_tec_ComM_BCMAntithftSts_Enum: accessed-variable=RTE_P_ComM_BCMAntithftSts_Enum.tec_ComM_BCMAntithftSts_Enum
              SEND_RTE_P_ComM_DCDCErrLvl_Enum_tec_ComM_DCDCErrLvl_Enum: accessed-variable=RTE_P_ComM_DCDCErrLvl_Enum.tec_ComM_DCDCErrLvl_Enum
              SEND_RTE_P_ComM_DCDCSide2OvrTempFlt_Flg_tec_ComM_DCDCSide2OvrTempFlt_Flg: accessed-variable=RTE_P_ComM_DCDCSide2OvrTempFlt_Flg.tec_ComM_DCDCSide2OvrTempFlt_Flg
              SEND_RTE_P_ComM_OBCErrLvl_Enum_tec_ComM_OBCErrLvl_Enum: accessed-variable=RTE_P_ComM_OBCErrLvl_Enum.tec_ComM_OBCErrLvl_Enum
              SEND_RTE_P_ComM_OBCSide2OvrTempFlt_Flg_tec_ComM_OBCSide2OvrTempFlt_Flg: accessed-variable=RTE_P_ComM_OBCSide2OvrTempFlt_Flg.tec_ComM_OBCSide2OvrTempFlt_Flg
              SEND_RTE_P_ComM_BMSKeepWrmReq_Enum_tec_ComM_BMSKeepWrmReq_Enum: accessed-variable=RTE_P_ComM_BMSKeepWrmReq_Enum.tec_ComM_BMSKeepWrmReq_Enum
              SEND_RTE_P_ComM_BMSKeepWrmSts_Enum_tec_ComM_BMSKeepWrmSts_Enum: accessed-variable=RTE_P_ComM_BMSKeepWrmSts_Enum.tec_ComM_BMSKeepWrmSts_Enum
              SEND_RTE_P_ComM_BMSRTCReq_Flg_tec_ComM_BMSRTCReq_Flg: accessed-variable=RTE_P_ComM_BMSRTCReq_Flg.tec_ComM_BMSRTCReq_Flg
              SEND_RTE_P_ComM_BCM05MsgErrInfo_Bus_tec_ComM_BCM05CRCDTCInfo_Bus: accessed-variable=RTE_P_ComM_BCM05MsgErrInfo_Bus.tec_ComM_BCM05CRCDTCInfo_Bus
              SEND_RTE_P_ComM_BCM05MsgErrInfo_Bus_tec_ComM_BCM05TimeoutDTCInfo_Bus: accessed-variable=RTE_P_ComM_BCM05MsgErrInfo_Bus.tec_ComM_BCM05TimeoutDTCInfo_Bus
              SEND_RTE_P_ComM_BMSErrRlySts_Enum_tec_ComM_BMSErrRlySts_Enum: accessed-variable=RTE_P_ComM_BMSErrRlySts_Enum.tec_ComM_BMSErrRlySts_Enum
              SEND_RTE_P_ComM_PODDCDC02Update_tec_ComM_PODDCDC02Update: accessed-variable=RTE_P_ComM_PODDCDC02Update.tec_ComM_PODDCDC02Update
              SEND_RTE_P_ComM_PODOBCSts03Update_tec_ComM_PODOBCSts03Update: accessed-variable=RTE_P_ComM_PODOBCSts03Update.tec_ComM_PODOBCSts03Update
        R_CANHandlerInput_Cyclic_500ms
          data-receive-point-by-arguments:
            5 x access:
              REC_SG_CGW_VIN1_SigGroup_SG_CGW_VIN1_SigGroup: accessed-variable=SG_CGW_VIN1_SigGroup.SG_CGW_VIN1_SigGroup
              REC_SG_CGW_VIN2_SigGroup_SG_CGW_VIN2_SigGroup: accessed-variable=SG_CGW_VIN2_SigGroup.SG_CGW_VIN2_SigGroup
              REC_SG_CGW_VIN3VER_SigGroup_SG_CGW_VIN3VER_SigGroup: accessed-variable=SG_CGW_VIN3VER_SigGroup.SG_CGW_VIN3VER_SigGroup
              REC_SG_MCU_Temperature_01_SigGroup_SG_MCU_Temperature_01_SigGroup: accessed-variable=SG_MCU_Temperature_01_SigGroup.SG_MCU_Temperature_01_SigGroup
              REC_SG_MCU_Temperature_02_SigGroup_SG_MCU_Temperature_02_SigGroup: accessed-variable=SG_MCU_Temperature_02_SigGroup.SG_MCU_Temperature_02_SigGroup
          data-send-points:
            access SEND_RTE_P_ComM_MCUTempOvrSts_Enum_tec_ComM_MCUTempOvrSts_Enum: accessed-variable=RTE_P_ComM_MCUTempOvrSts_Enum.tec_ComM_MCUTempOvrSts_Enum
        R_CANHandlerInput_Cyclic_1000ms
          data-receive-point-by-arguments:
            7 x access:
              REC_SG_BMS_BatInfor_{01..03}_SigGroup_SG_BMS_BatInfor_{01..03}_SigGroup: accessed-variable=SG_BMS_BatInfor_{01..03}_SigGroup.SG_BMS_BatInfor_{01..03}_SigGroup
              REC_SG_BMS_Charge_03_SigGroup_SG_BMS_Charge_03_SigGroup: accessed-variable=SG_BMS_Charge_03_SigGroup.SG_BMS_Charge_03_SigGroup
              REC_SG_BMS_PRO_SigGroup_SG_BMS_PRO_SigGroup: accessed-variable=SG_BMS_PRO_SigGroup.SG_BMS_PRO_SigGroup
              REC_SG_BMS_VersionInfor_SigGroup_SG_BMS_VersionInfor_SigGroup: accessed-variable=SG_BMS_VersionInfor_SigGroup.SG_BMS_VersionInfor_SigGroup
              REC_SG_IVI_OdometerInfor_SigGroup_SG_IVI_OdometerInfor_SigGroup: accessed-variable=SG_IVI_OdometerInfor_SigGroup.SG_IVI_OdometerInfor_SigGroup
          data-send-points:
            access SEND_RTE_P_ComM_BMSBattRateCp_Ah_tec_ComM_BMSBattRateCp_Ah: accessed-variable=RTE_P_ComM_BMSBattRateCp_Ah.tec_ComM_BMSBattRateCp_Ah
            access SEND_RTE_P_ComM_BMSBattRemnCp_Ah_tec_ComM_BMSBattRemnCp_Ah: accessed-variable=RTE_P_ComM_BMSBattRemnCp_Ah.tec_ComM_BMSBattRemnCp_Ah
            access SEND_RTE_P_ComM_IVIOdometerInfo_tec_ComM_IVIOdometerInfo: accessed-variable=RTE_P_ComM_IVIOdometerInfo.tec_ComM_IVIOdometerInfo
        R_CANHandlerOutput_Cyclic_10ms
          data-receive-point-by-arguments:
            22 x access:
              REC_RTE_R_ChassisMgmt_BrkSts_Enum_tec_ChassisMgmt_BrkSts_Enum: accessed-variable=RTE_R_ChassisMgmt_BrkSts_Enum.tec_ChassisMgmt_BrkSts_Enum
              REC_RTE_R_ChassisMgmt_OnePedlCtrlReqStdlSts_Flg_tec_ChassisMgmt_OnePedlCtrlReqStdlSts_Flg: accessed-variable=RTE_R_ChassisMgmt_OnePedlCtrlReqStdlSts_Flg.tec_ChassisMgmt_OnePedlCtrlReqStdlSts_Flg
              REC_RTE_R_ErrMgmt_VehErrLvl_Enum_tec_ErrMgmt_VehErrLvl_Enum: accessed-variable=RTE_R_ErrMgmt_VehErrLvl_Enum.tec_ErrMgmt_VehErrLvl_Enum
              REC_RTE_R_FctSftyMon_AccrPedlTqOverFltInfo_Bus_tec_FctSftyMon_AccrPedlTqOverFltInfo_Bus: accessed-variable=RTE_R_FctSftyMon_AccrPedlTqOverFltInfo_Bus.tec_FctSftyMon_AccrPedlTqOverFltInfo_Bus
              REC_RTE_R_FctSftyMon_ActGear_Enum_tec_FctSftyMon_ActGear_Enum: accessed-variable=RTE_R_FctSftyMon_ActGear_Enum.tec_FctSftyMon_ActGear_Enum
              REC_RTE_R_FctSftyMon_CrpCtrlTqOverFltInfo_Bus_tec_FctSftyMon_CrpCtrlTqOverFltInfo_Bus: accessed-variable=RTE_R_FctSftyMon_CrpCtrlTqOverFltInfo_Bus.tec_FctSftyMon_CrpCtrlTqOverFltInfo_Bus
              REC_RTE_R_FctSftyMon_DesVehDecelSpdOverFltInfo_Bus_tec_FctSftyMon_DesVehDecelSpdOverFltInfo_Bus: accessed-variable=RTE_R_FctSftyMon_DesVehDecelSpdOverFltInfo_Bus.tec_FctSftyMon_DesVehDecelSpdOverFltInfo_Bus
              REC_RTE_R_HvMgmt_MCUReqSts_Enum_tec_HvMgmt_MCUReqSts_Enum: accessed-variable=RTE_R_HvMgmt_MCUReqSts_Enum.tec_HvMgmt_MCUReqSts_Enum
              REC_RTE_R_TorqPahMgmt_DesMotTq_Nm_tec_TorqPahMgmt_DesMotTq_Nm: accessed-variable=RTE_R_TorqPahMgmt_DesMotTq_Nm.tec_TorqPahMgmt_DesMotTq_Nm
              REC_RTE_R_TorqPahMgmt_MotActTqVld_Flg_tec_TorqPahMgmt_MotActTqVld_Flg: accessed-variable=RTE_R_TorqPahMgmt_MotActTqVld_Flg.tec_TorqPahMgmt_MotActTqVld_Flg
              REC_RTE_R_TorqPahMgmt_MotActTq_Nm_tec_TorqPahMgmt_MotActTq_Nm: accessed-variable=RTE_R_TorqPahMgmt_MotActTq_Nm.tec_TorqPahMgmt_MotActTq_Nm
              REC_RTE_R_TorqPahMgmt_ReqMotDampSts_Enum_tec_TorqPahMgmt_ReqMotDampSts_Enum: accessed-variable=RTE_R_TorqPahMgmt_ReqMotDampSts_Enum.tec_TorqPahMgmt_ReqMotDampSts_Enum
              REC_RTE_R_TorqPahMgmt_WhlActTqVld_Flg_tec_TorqPahMgmt_WhlActTqVld_Flg: accessed-variable=RTE_R_TorqPahMgmt_WhlActTqVld_Flg.tec_TorqPahMgmt_WhlActTqVld_Flg
              REC_RTE_R_TorqPahMgmt_WhlActTq_Nm_tec_TorqPahMgmt_WhlActTq_Nm: accessed-variable=RTE_R_TorqPahMgmt_WhlActTq_Nm.tec_TorqPahMgmt_WhlActTq_Nm
              REC_RTE_R_LvMgmt_KL15ActSts_Flg_tec_LvMgmt_KL15ActSts_Flg: accessed-variable=RTE_R_LvMgmt_KL15ActSts_Flg.tec_LvMgmt_KL15ActSts_Flg
              REC_RTE_R_LvMgmt_AppNMReqInfo_tec_LvMgmt_AppNMReqInfo: accessed-variable=RTE_R_LvMgmt_AppNMReqInfo.tec_LvMgmt_AppNMReqInfo
              REC_RTE_R_LvMgmt_KL15CtrlReq_Flg_tec_LvMgmt_KL15CtrlReq_Flg: accessed-variable=RTE_R_LvMgmt_KL15CtrlReq_Flg.tec_LvMgmt_KL15CtrlReq_Flg
              REC_RTE_R_ChrMgmt_ChrgPwr_kW_tec_ChrMgmt_VCUDispChrgPwr_kW: accessed-variable=RTE_R_ChrMgmt_ChrgPwr_kW.tec_ChrMgmt_VCUDispChrgPwr_kW
              REC_RTE_R_ComM_BSBatVltHlResInfo_tec_ComM_BSBatVltHlResInfo: accessed-variable=RTE_R_ComM_BSBatVltHlResInfo.tec_ComM_BSBatVltHlResInfo
              REC_RTE_R_ComM_BSBattSOC_pct_tec_ComM_BSBattSOC_pct: accessed-variable=RTE_R_ComM_BSBattSOC_pct.tec_ComM_BSBattSOC_pct
              REC_RTE_R_ComM_TriggerASWMsgReqInfo_tec_ComM_TriggerASWMsgReqInfo: accessed-variable=RTE_R_ComM_TriggerASWMsgReqInfo.tec_ComM_TriggerASWMsgReqInfo
              REC_RTE_R_TorqPahMgmt_MotDampLmtTq_tec_TorqPahMgmt_MotDampLmtTq: accessed-variable=RTE_R_TorqPahMgmt_MotDampLmtTq.tec_TorqPahMgmt_MotDampLmtTq
          data-send-points:
            access SEND_SG_VCU_MCU_02_SigGroup_SG_VCU_MCU_02_SigGroup: accessed-variable=SG_VCU_MCU_02_SigGroup.SG_VCU_MCU_02_SigGroup
            access SEND_SG_VCU_IBS_01_SigGroup_SG_VCU_IBS_01_SigGroup: accessed-variable=SG_VCU_IBS_01_SigGroup.SG_VCU_IBS_01_SigGroup
            access SEND_SG_VCU_MCU_03_SigGroup_1_SG_VCU_MCU_03_SigGroup: accessed-variable=SG_VCU_MCU_03_SigGroup_1.SG_VCU_MCU_03_SigGroup
        R_CANHandlerOutput_Cyclic_20ms
          data-receive-point-by-arguments:
            41 x access:
              REC_RTE_R_ChassisMgmt_AccrPedlDesTq_Nm_tec_ChassisMgmt_AccrPedlDesTq_Nm: accessed-variable=RTE_R_ChassisMgmt_AccrPedlDesTq_Nm.tec_ChassisMgmt_AccrPedlDesTq_Nm
              REC_RTE_R_ChassisMgmt_AccrPedlKdStsInfo_tec_ChassisMgmt_AccrPedlKdStsInfo: accessed-variable=RTE_R_ChassisMgmt_AccrPedlKdStsInfo.tec_ChassisMgmt_AccrPedlKdStsInfo
              REC_RTE_R_ChassisMgmt_AccrPedlRawPosnInfo_tec_ChassisMgmt_AccrPedlRawPosnInfo: accessed-variable=RTE_R_ChassisMgmt_AccrPedlRawPosnInfo.tec_ChassisMgmt_AccrPedlRawPosnInfo
              REC_RTE_R_ChassisMgmt_AccrPedlVld_Flg_tec_ChassisMgmt_AccrPedlVld_Flg: accessed-variable=RTE_R_ChassisMgmt_AccrPedlVld_Flg.tec_ChassisMgmt_AccrPedlVld_Flg
              REC_RTE_R_ChassisMgmt_BrkCmpSts_Enum_tec_ChassisMgmt_BrkCmpSts_Enum: accessed-variable=RTE_R_ChassisMgmt_BrkCmpSts_Enum.tec_ChassisMgmt_BrkCmpSts_Enum
              REC_RTE_R_ChassisMgmt_DesVehDecelSpd_mps2q_tec_ChassisMgmt_DesVehDecelSpd_mps2q: accessed-variable=RTE_R_ChassisMgmt_DesVehDecelSpd_mps2q.tec_ChassisMgmt_DesVehDecelSpd_mps2q
              REC_RTE_R_ChassisMgmt_DrvAsscCtrlOvrdSts_Flg_tec_ChassisMgmt_DrvAsscCtrlOvrdSts_Flg: accessed-variable=RTE_R_ChassisMgmt_DrvAsscCtrlOvrdSts_Flg.tec_ChassisMgmt_DrvAsscCtrlOvrdSts_Flg
              REC_RTE_R_ChassisMgmt_IBSApsReqTqActv_Flg_tec_ChassisMgmt_IBSApsReqTqActv_Flg: accessed-variable=RTE_R_ChassisMgmt_IBSApsReqTqActv_Flg.tec_ChassisMgmt_IBSApsReqTqActv_Flg
              REC_RTE_R_ChassisMgmt_IBSApsReqTqAvl_Flg_tec_ChassisMgmt_IBSApsReqTqAvl_Flg: accessed-variable=RTE_R_ChassisMgmt_IBSApsReqTqAvl_Flg.tec_ChassisMgmt_IBSApsReqTqAvl_Flg
              REC_RTE_R_ChassisMgmt_IBSIntvTqActv_tec_ChassisMgmt_IBSIntvTqActv: accessed-variable=RTE_R_ChassisMgmt_IBSIntvTqActv.tec_ChassisMgmt_IBSIntvTqActv
              REC_RTE_R_ChassisMgmt_IBSVlcReqTqActv_Flg_tec_ChassisMgmt_IBSVlcReqTqActv_Flg: accessed-variable=RTE_R_ChassisMgmt_IBSVlcReqTqActv_Flg.tec_ChassisMgmt_IBSVlcReqTqActv_Flg
              REC_RTE_R_ChassisMgmt_IBSVlcReqTqAvl_Flg_tec_ChassisMgmt_IBSVlcReqTqAvl_Flg: accessed-variable=RTE_R_ChassisMgmt_IBSVlcReqTqAvl_Flg.tec_ChassisMgmt_IBSVlcReqTqAvl_Flg
              REC_RTE_R_ChassisMgmt_RgnTqCapVld_Flg_tec_ChassisMgmt_RgnTqCapVld_Flg: accessed-variable=RTE_R_ChassisMgmt_RgnTqCapVld_Flg.tec_ChassisMgmt_RgnTqCapVld_Flg
              REC_RTE_R_ChassisMgmt_RgnTqCap_Nm_tec_ChassisMgmt_RgnTqCap_Nm: accessed-variable=RTE_R_ChassisMgmt_RgnTqCap_Nm.tec_ChassisMgmt_RgnTqCap_Nm
              REC_RTE_R_ChassisMgmt_VehDecelSpdSts_Flg_tec_ChassisMgmt_VehDecelSpdSts_Flg: accessed-variable=RTE_R_ChassisMgmt_VehDecelSpdSts_Flg.tec_ChassisMgmt_VehDecelSpdSts_Flg
              REC_RTE_R_ChassisMgmt_VehStbCtrlTqAvl_Flg_tec_ChassisMgmt_VehStbCtrlTqAvl_Flg: accessed-variable=RTE_R_ChassisMgmt_VehStbCtrlTqAvl_Flg.tec_ChassisMgmt_VehStbCtrlTqAvl_Flg
              REC_RTE_R_ChassisMgmt_VirtAccrPedlPosnInfo_tec_ChassisMgmt_VirtAccrPedlPosnInfo: accessed-variable=RTE_R_ChassisMgmt_VirtAccrPedlPosnInfo.tec_ChassisMgmt_VirtAccrPedlPosnInfo
              REC_RTE_R_ChassisMgmt_VirtAccrPedlVldInfo_tec_ChassisMgmt_VirtAccrPedlVldInfo: accessed-variable=RTE_R_ChassisMgmt_VirtAccrPedlVldInfo.tec_ChassisMgmt_VirtAccrPedlVldInfo
              REC_RTE_R_ChrMgmt_ChrgSts_Enum_tec_ChrMgmt_ChrgSts_Enum: accessed-variable=RTE_R_ChrMgmt_ChrgSts_Enum.tec_ChrMgmt_ChrgSts_Enum
              REC_RTE_R_ChrMgmt_PosRlyReqSts_Enum_tec_ChrMgmt_PosRlyReqSts_Enum: accessed-variable=RTE_R_ChrMgmt_PosRlyReqSts_Enum.tec_ChrMgmt_PosRlyReqSts_Enum
              REC_RTE_R_DCChrMgmt_IRMeasSwtCtrl_Enum_tec_DCChrMgmt_IRMeasSwtCtrl_Enum: accessed-variable=RTE_R_DCChrMgmt_IRMeasSwtCtrl_Enum.tec_DCChrMgmt_IRMeasSwtCtrl_Enum
              REC_RTE_R_EgyMgmt_BMSTarThermLvl_Enum_tec_EgyMgmt_BMSTarThermLvl_Enum: accessed-variable=RTE_R_EgyMgmt_BMSTarThermLvl_Enum.tec_EgyMgmt_BMSTarThermLvl_Enum
              REC_RTE_R_EgyMgmt_EgyMgmtWarn_Enum_tec_EgyMgmt_EgyMgmtWarn_Enum: accessed-variable=RTE_R_EgyMgmt_EgyMgmtWarn_Enum.tec_EgyMgmt_EgyMgmtWarn_Enum
              REC_RTE_R_GearMgmt_TarGear_Enum_tec_GearMgmt_TarGear_Enum: accessed-variable=RTE_R_GearMgmt_TarGear_Enum.tec_GearMgmt_TarGear_Enum
              REC_RTE_R_HvMgmt_ReqModBMS_Enum_tec_HvMgmt_ReqModBMS_Enum: accessed-variable=RTE_R_HvMgmt_ReqModBMS_Enum.tec_HvMgmt_ReqModBMS_Enum
              REC_RTE_R_LvMgmt_VCUlimLvlInfo_tec_LvMgmt_VCUlimLvlInfo: accessed-variable=RTE_R_LvMgmt_VCUlimLvlInfo.tec_LvMgmt_VCUlimLvlInfo
              REC_RTE_R_ModMgmt_ActDrvMod_Enum_tec_ModMgmt_ActDrvMod_Enum: accessed-variable=RTE_R_ModMgmt_ActDrvMod_Enum.tec_ModMgmt_ActDrvMod_Enum
              REC_RTE_R_ModMgmt_ActRgnSts_Enum_tec_ModMgmt_ActRgnSts_Enum: accessed-variable=RTE_R_ModMgmt_ActRgnSts_Enum.tec_ModMgmt_ActRgnSts_Enum
              REC_RTE_R_ModMgmt_DrvModSwtWarn_Enum_tec_ModMgmt_DrvModSwtWarn_Enum: accessed-variable=RTE_R_ModMgmt_DrvModSwtWarn_Enum.tec_ModMgmt_DrvModSwtWarn_Enum
              REC_RTE_R_ModMgmt_HvSts_Enum_tec_ModMgmt_HvSts_Enum: accessed-variable=RTE_R_ModMgmt_HvSts_Enum.tec_ModMgmt_HvSts_Enum
              REC_RTE_R_TorqPahMgmt_EmacQstyMaxTq_Nm_tec_TorqPahMgmt_EmacQstyMaxTq_Nm: accessed-variable=RTE_R_TorqPahMgmt_EmacQstyMaxTq_Nm.tec_TorqPahMgmt_EmacQstyMaxTq_Nm
              REC_RTE_R_TorqPahMgmt_EmacQstyMinTq_Nm_tec_TorqPahMgmt_EmacQstyMinTq_Nm: accessed-variable=RTE_R_TorqPahMgmt_EmacQstyMinTq_Nm.tec_TorqPahMgmt_EmacQstyMinTq_Nm
              REC_RTE_R_VehMot_RegenBrkLiVld_Flg_tec_VehMot_RegenBrkLiVld_Flg: accessed-variable=RTE_R_VehMot_RegenBrkLiVld_Flg.tec_VehMot_RegenBrkLiVld_Flg
              REC_RTE_R_VehMot_RegenBrkLi_Flg_tec_VehMot_RegenBrkLi_Flg: accessed-variable=RTE_R_VehMot_RegenBrkLi_Flg.tec_VehMot_RegenBrkLi_Flg
              REC_RTE_R_VehMot_VehSpdABS_kph_tec_VehMot_VehSpdABS_kph: accessed-variable=RTE_R_VehMot_VehSpdABS_kph.tec_VehMot_VehSpdABS_kph
              REC_RTE_R_VehMot_VehSpdVld_Flg_tec_VehMot_VehSpdVld_Flg: accessed-variable=RTE_R_VehMot_VehSpdVld_Flg.tec_VehMot_VehSpdVld_Flg
              REC_RTE_R_ChassisMgmt_BrkCmpWarn_Enum_tec_ChassisMgmt_BrkCmpWarn_Enum: accessed-variable=RTE_R_ChassisMgmt_BrkCmpWarn_Enum.tec_ChassisMgmt_BrkCmpWarn_Enum
              REC_RTE_R_ComM_TriggerASWMsgReqInfo_tec_ComM_TriggerASWMsgReqInfo: accessed-variable=RTE_R_ComM_TriggerASWMsgReqInfo.tec_ComM_TriggerASWMsgReqInfo
              REC_RTE_R_FctSftyMon_EPBReq_tec_FctSftyMon_EPBReq: accessed-variable=RTE_R_FctSftyMon_EPBReq.tec_FctSftyMon_EPBReq
              REC_RTE_R_TorqPahMgmt_MaxVehSpdLmtTq_Nm_tec_TorqPahMgmt_MaxVehSpdLmtTq_Nm: accessed-variable=RTE_R_TorqPahMgmt_MaxVehSpdLmtTq_Nm.tec_TorqPahMgmt_MaxVehSpdLmtTq_Nm
              REC_RTE_R_ChassisMgmt_CrpCtrlDesTq_Nm_tec_ChassisMgmt_CrpCtrlDesTq_Nm: accessed-variable=RTE_R_ChassisMgmt_CrpCtrlDesTq_Nm.tec_ChassisMgmt_CrpCtrlDesTq_Nm
          data-send-points:
            6 x access:
              SEND_SG_VCU_AccPedal_SigGroup_SG_VCU_AccPedal_SigGroup: accessed-variable=SG_VCU_AccPedal_SigGroup.SG_VCU_AccPedal_SigGroup
              SEND_SG_VCU_BMS_SigGroup_SG_VCU_BMS_SigGroup: accessed-variable=SG_VCU_BMS_SigGroup.SG_VCU_BMS_SigGroup
              SEND_SG_VCU_MCU_05_SigGroup_SG_VCU_MCU_05_SigGroup: accessed-variable=SG_VCU_MCU_05_SigGroup.SG_VCU_MCU_05_SigGroup
              SEND_SG_VCU_Chassis_01_SigGroup_SG_VCU_Chassis_01_SigGroup: accessed-variable=SG_VCU_Chassis_01_SigGroup.SG_VCU_Chassis_01_SigGroup
              SEND_RTE_P_MilCal_VCU_VehicleSpeed_tec_MilCal_VCU_VehicleSpeed: accessed-variable=RTE_P_MilCal_VCU_VehicleSpeed.tec_MilCal_VCU_VehicleSpeed
              SEND_RTE_P_MilCal_VCU_VehicleSpeedValid_tec_MilCal_VCU_VehicleSpeedValid: accessed-variable=RTE_P_MilCal_VCU_VehicleSpeedValid.tec_MilCal_VCU_VehicleSpeedValid
        R_CANHandlerOutput_Cyclic_50ms
          data-receive-point-by-arguments:
            6 x access:
              REC_RTE_R_DCChrMgmt_DCFCClsReq_Flg_tec_DCChrMgmt_DCFCClsReq_Flg: accessed-variable=RTE_R_DCChrMgmt_DCFCClsReq_Flg.tec_DCChrMgmt_DCFCClsReq_Flg
              REC_RTE_R_OBCMgmt_ElectcLockCtrlCmd_Enum_tec_OBCMgmt_ElectcLockCtrlCmd_Enum: accessed-variable=RTE_R_OBCMgmt_ElectcLockCtrlCmd_Enum.tec_OBCMgmt_ElectcLockCtrlCmd_Enum
              REC_RTE_R_OBCMgmt_OBCEnaCmd_Enum_tec_OBCMgmt_OBCEnaCmd_Enum: accessed-variable=RTE_R_OBCMgmt_OBCEnaCmd_Enum.tec_OBCMgmt_OBCEnaCmd_Enum
              REC_RTE_R_OBCMgmt_ReqOBCIDc_A_tec_OBCMgmt_ReqOBCIDc_A: accessed-variable=RTE_R_OBCMgmt_ReqOBCIDc_A.tec_OBCMgmt_ReqOBCIDc_A
              REC_RTE_R_OBCMgmt_S2SwtCtrlCmd_Enum_tec_OBCMgmt_S2SwtCtrlCmd_Enum: accessed-variable=RTE_R_OBCMgmt_S2SwtCtrlCmd_Enum.tec_OBCMgmt_S2SwtCtrlCmd_Enum
              REC_RTE_R_ComM_TriggerASWMsgReqInfo_tec_ComM_TriggerASWMsgReqInfo: accessed-variable=RTE_R_ComM_TriggerASWMsgReqInfo.tec_ComM_TriggerASWMsgReqInfo
          data-send-points:
            access SEND_SG_VCU_POD_SigGroup_SG_VCU_POD_SigGroup: accessed-variable=SG_VCU_POD_SigGroup.SG_VCU_POD_SigGroup
        R_CANHandlerOutput_Cyclic_100ms
          data-receive-point-by-arguments:
            23 x access:
              REC_RTE_R_ChassisMgmt_BrkCmpSts_Enum_tec_ChassisMgmt_BrkCmpSts_Enum: accessed-variable=RTE_R_ChassisMgmt_BrkCmpSts_Enum.tec_ChassisMgmt_BrkCmpSts_Enum
              REC_RTE_R_ChrMgmt_ChrgMemFlt_Flg_tec_ChrMgmt_ChrgMemFlt_Flg: accessed-variable=RTE_R_ChrMgmt_ChrgMemFlt_Flg.tec_ChrMgmt_ChrgMemFlt_Flg
              REC_RTE_R_ChrMgmt_ChrgProcCmt_Enum_tec_ChrMgmt_ChrgProcCmt_Enum: accessed-variable=RTE_R_ChrMgmt_ChrgProcCmt_Enum.tec_ChrMgmt_ChrgProcCmt_Enum
              REC_RTE_R_ChrMgmt_ChrgTim_min_tec_ChrMgmt_ChrgTim_min: accessed-variable=RTE_R_ChrMgmt_ChrgTim_min.tec_ChrMgmt_ChrgTim_min
              REC_RTE_R_ChrMgmt_OBCSideSngDchaEgy_kWh_tec_ChrMgmt_OBCSideSngDchaEgy_kWh: accessed-variable=RTE_R_ChrMgmt_OBCSideSngDchaEgy_kWh.tec_ChrMgmt_OBCSideSngDchaEgy_kWh
              REC_RTE_R_ChrMgmt_SngChrgEgy_kWh_tec_ChrMgmt_SngChrgEgy_kWh: accessed-variable=RTE_R_ChrMgmt_SngChrgEgy_kWh.tec_ChrMgmt_SngChrgEgy_kWh
              REC_RTE_R_ChrMgmt_VCUCalcdPODIDc_A_tec_ChrMgmt_VCUCalcdPODIDc_A: accessed-variable=RTE_R_ChrMgmt_VCUCalcdPODIDc_A.tec_ChrMgmt_VCUCalcdPODIDc_A
              REC_RTE_R_DCChrMgmt_MaxChrgIDc_A_tec_DCChrMgmt_MaxChrgIDc_A: accessed-variable=RTE_R_DCChrMgmt_MaxChrgIDc_A.tec_DCChrMgmt_MaxChrgIDc_A
              REC_RTE_R_DCChrMgmt_MaxChrgUDc_V_tec_DCChrMgmt_MaxChrgUDc_V: accessed-variable=RTE_R_DCChrMgmt_MaxChrgUDc_V.tec_DCChrMgmt_MaxChrgUDc_V
              REC_RTE_R_DCChrMgmt_MinChrgIDc_A_tec_DCChrMgmt_MinChrgIDc_A: accessed-variable=RTE_R_DCChrMgmt_MinChrgIDc_A.tec_DCChrMgmt_MinChrgIDc_A
              REC_RTE_R_DCChrMgmt_MinChrgUDc_V_tec_DCChrMgmt_MinChrgUDc_V: accessed-variable=RTE_R_DCChrMgmt_MinChrgUDc_V.tec_DCChrMgmt_MinChrgUDc_V
              REC_RTE_R_EgyMgmt_AvgMCUPwrCnsCalcn_Kw_tec_EgyMgmt_AvgMCUPwrCnsCalcn_Kw: accessed-variable=RTE_R_EgyMgmt_AvgMCUPwrCnsCalcn_Kw.tec_EgyMgmt_AvgMCUPwrCnsCalcn_Kw
              REC_RTE_R_EgyMgmt_DCDCPwrLmt_Kw_tec_EgyMgmt_DCDCPwrLmt_Kw: accessed-variable=RTE_R_EgyMgmt_DCDCPwrLmt_Kw.tec_EgyMgmt_DCDCPwrLmt_Kw
              REC_RTE_R_EgyMgmt_PermtPckPTC_Flg_tec_EgyMgmt_PermtPckPTC_Flg: accessed-variable=RTE_R_EgyMgmt_PermtPckPTC_Flg.tec_EgyMgmt_PermtPckPTC_Flg
              REC_RTE_R_EgyMgmt_TCUPwrAllwd_W_tec_EgyMgmt_TCUPwrAllwd_W: accessed-variable=RTE_R_EgyMgmt_TCUPwrAllwd_W.tec_EgyMgmt_TCUPwrAllwd_W
              REC_RTE_R_EgyMgmt_V2LDisChgPwrLmtInfo_tec_EgyMgmt_V2LDisChgPwrLmtInfo: accessed-variable=RTE_R_EgyMgmt_V2LDisChgPwrLmtInfo.tec_EgyMgmt_V2LDisChgPwrLmtInfo
              REC_RTE_R_HvMgmt_DCDCDmdLvUDc_V_tec_HvMgmt_DCDCDmdLvUDc_V: accessed-variable=RTE_R_HvMgmt_DCDCDmdLvUDc_V.tec_HvMgmt_DCDCDmdLvUDc_V
              REC_RTE_R_HvMgmt_ReqDCDCMod_Enum_tec_HvMgmt_ReqDCDCMod_Enum: accessed-variable=RTE_R_HvMgmt_ReqDCDCMod_Enum.tec_HvMgmt_ReqDCDCMod_Enum
              REC_RTE_R_HvMgmt_ReqTCUMod_Enum_tec_HvMgmt_ReqTCUMod_Enum: accessed-variable=RTE_R_HvMgmt_ReqTCUMod_Enum.tec_HvMgmt_ReqTCUMod_Enum
              REC_RTE_R_OBCMgmt_MnyUnlckCmt_Enum_tec_OBCMgmt_MnyUnlckCmt_Enum: accessed-variable=RTE_R_OBCMgmt_MnyUnlckCmt_Enum.tec_OBCMgmt_MnyUnlckCmt_Enum
              REC_RTE_R_RngEstimn_DynDrvMilg_km_tec_RngEstimn_DynDrvMilg_km: accessed-variable=RTE_R_RngEstimn_DynDrvMilg_km.tec_RngEstimn_DynDrvMilg_km
              REC_RTE_R_TorqPahMgmt_FwdMaxSpdSts_Flg_tec_TorqPahMgmt_FwdMaxSpdSts_Flg: accessed-variable=RTE_R_TorqPahMgmt_FwdMaxSpdSts_Flg.tec_TorqPahMgmt_FwdMaxSpdSts_Flg
              REC_RTE_R_ComM_TriggerASWMsgReqInfo_tec_ComM_TriggerASWMsgReqInfo: accessed-variable=RTE_R_ComM_TriggerASWMsgReqInfo.tec_ComM_TriggerASWMsgReqInfo
          data-send-points:
            6 x access:
              SEND_SG_VCU_05_SigGroup_SG_VCU_05_SigGroup: accessed-variable=SG_VCU_05_SigGroup.SG_VCU_05_SigGroup
              SEND_SG_VCU_06_SigGroup_SG_VCU_06_SigGroup: accessed-variable=SG_VCU_06_SigGroup.SG_VCU_06_SigGroup
              SEND_SG_VCU_DCDC_SigGroup_SG_VCU_DCDC_SigGroup: accessed-variable=SG_VCU_DCDC_SigGroup.SG_VCU_DCDC_SigGroup
              SEND_SG_VCU_TCU_SigGroup_SG_VCU_TCU_SigGroup: accessed-variable=SG_VCU_TCU_SigGroup.SG_VCU_TCU_SigGroup
              SEND_SG_VCU_03_SigGroup_SG_VCU_03_SigGroup: accessed-variable=SG_VCU_03_SigGroup.SG_VCU_03_SigGroup
              SEND_SG_VCU_04_SigGroup_SG_VCU_04_SigGroup: accessed-variable=SG_VCU_04_SigGroup.SG_VCU_04_SigGroup
        R_CANHandlerOutput_Cyclic_200ms
          data-receive-point-by-arguments:
            33 x access:
              REC_RTE_R_ChrMgmt_ChrgAbortRsn_Enum_tec_ChrMgmt_ChrgAbortRsn_Enum: accessed-variable=RTE_R_ChrMgmt_ChrgAbortRsn_Enum.tec_ChrMgmt_ChrgAbortRsn_Enum
              REC_RTE_R_ChrMgmt_ChrgTarSOC_pct_tec_ChrMgmt_ChrgTarSOC_pct: accessed-variable=RTE_R_ChrMgmt_ChrgTarSOC_pct.tec_ChrMgmt_ChrgTarSOC_pct
              REC_RTE_R_ChrMgmt_ChrgnRemnTim_min_tec_ChrgMgmt_ChrgnRemnTim_min: accessed-variable=RTE_R_ChrMgmt_ChrgnRemnTim_min.tec_ChrgMgmt_ChrgnRemnTim_min
              REC_RTE_R_ChrMgmt_DchaAbortSOC_pct_tec_ChrMgmt_DchaAbortSOC_pct: accessed-variable=RTE_R_ChrMgmt_DchaAbortSOC_pct.tec_ChrMgmt_DchaAbortSOC_pct
              REC_RTE_R_ChrMgmt_PlugSts_Enum_tec_ChrMgmt_PlugSts_Enum: accessed-variable=RTE_R_ChrMgmt_PlugSts_Enum.tec_ChrMgmt_PlugSts_Enum
              REC_RTE_R_ChrMgmt_VCUCalcdPODIDc_A_tec_ChrMgmt_VCUCalcdPODIDc_A: accessed-variable=RTE_R_ChrMgmt_VCUCalcdPODIDc_A.tec_ChrMgmt_VCUCalcdPODIDc_A
              REC_RTE_R_ChrMgmt_VCUDispChrgI_A_tec_ChrMgmt_VCUDispChrgI_A: accessed-variable=RTE_R_ChrMgmt_VCUDispChrgI_A.tec_ChrMgmt_VCUDispChrgI_A
              REC_RTE_R_ChrMgmt_VCUDispChrgU_V_tec_ChrMgmt_VCUDispChrgU_V: accessed-variable=RTE_R_ChrMgmt_VCUDispChrgU_V.tec_ChrMgmt_VCUDispChrgU_V
              REC_RTE_R_ChrMrmt_DchaAbortRsn_Enum_tec_ChrMgmt_DchaAbortRsn_Enum: accessed-variable=RTE_R_ChrMrmt_DchaAbortRsn_Enum.tec_ChrMgmt_DchaAbortRsn_Enum
              REC_RTE_R_ErrMgmt_DCDCFailLamp_Flg_tec_ErrMgmt_DCDCFailLamp_Flg: accessed-variable=RTE_R_ErrMgmt_DCDCFailLamp_Flg.tec_ErrMgmt_DCDCFailLamp_Flg
              REC_RTE_R_ErrMgmt_DrvMotTempOvrLamp_Bus_tec_ErrMgmt_DrvMotTempOvrLamp_Bus: accessed-variable=RTE_R_ErrMgmt_DrvMotTempOvrLamp_Bus.tec_ErrMgmt_DrvMotTempOvrLamp_Bus
              REC_RTE_R_ErrMgmt_HvBattFailLamp_tec_ErrMgmt_HvBattFailLamp: accessed-variable=RTE_R_ErrMgmt_HvBattFailLamp.tec_ErrMgmt_HvBattFailLamp
              REC_RTE_R_ErrMgmt_HvBattTempOvrLamp_Bus_tec_ErrMgmt_HvBattTempOvrLamp_Bus: accessed-variable=RTE_R_ErrMgmt_HvBattTempOvrLamp_Bus.tec_ErrMgmt_HvBattTempOvrLamp_Bus
              REC_RTE_R_ErrMgmt_InslaFlt_Bus_tec_ErrMgmt_InslaFlt_Bus: accessed-variable=RTE_R_ErrMgmt_InslaFlt_Bus.tec_ErrMgmt_InslaFlt_Bus
              REC_RTE_R_ErrMgmt_LimpHomeLamp_Flg_tec_ErrMgmt_LimpHomeLamp_Flg: accessed-variable=RTE_R_ErrMgmt_LimpHomeLamp_Flg.tec_ErrMgmt_LimpHomeLamp_Flg
              REC_RTE_R_ErrMgmt_MCUFltLamp_tec_ErrMgmt_MCUFltLamp: accessed-variable=RTE_R_ErrMgmt_MCUFltLamp.tec_ErrMgmt_MCUFltLamp
              REC_RTE_R_ErrMgmt_SysFailLamp_Enum_tec_ErrMgmt_SysFailLamp_Enum: accessed-variable=RTE_R_ErrMgmt_SysFailLamp_Enum.tec_ErrMgmt_SysFailLamp_Enum
              REC_RTE_R_ErrMgmt_VehHVIL_Bus_tec_ErrMgmt_VehHVIL_Bus: accessed-variable=RTE_R_ErrMgmt_VehHVIL_Bus.tec_ErrMgmt_VehHVIL_Bus
              REC_RTE_R_GearMgmt_InvldGearSel_Enum_tec_GearMgmt_InvldGearSel_Enum: accessed-variable=RTE_R_GearMgmt_InvldGearSel_Enum.tec_GearMgmt_InvldGearSel_Enum
              REC_RTE_R_HvMgmt_HVConnFlt_Flg_tec_HvMgmt_HVConnFlt_Flg: accessed-variable=RTE_R_HvMgmt_HVConnFlt_Flg.tec_HvMgmt_HVConnFlt_Flg
              REC_RTE_R_LvMgmt_ReachLimStdInfo_tec_LvMgmt_ReachLimStdInfo: accessed-variable=RTE_R_LvMgmt_ReachLimStdInfo.tec_LvMgmt_ReachLimStdInfo
              REC_RTE_R_ModMgmt_HvSts_Enum_tec_ModMgmt_HvSts_Enum: accessed-variable=RTE_R_ModMgmt_HvSts_Enum.tec_ModMgmt_HvSts_Enum
              REC_RTE_R_TorqPahMgmt_FwdMaxVehSpd_Enum_tec_TorqPahMgmt_FwdMaxVehSpd_Enum: accessed-variable=RTE_R_TorqPahMgmt_FwdMaxVehSpd_Enum.tec_TorqPahMgmt_FwdMaxVehSpd_Enum
              REC_RTE_R_ChrMgmt_ChrgPwr_kW_tec_ChrMgmt_VCUDispChrgPwr_kW: accessed-variable=RTE_R_ChrMgmt_ChrgPwr_kW.tec_ChrMgmt_VCUDispChrgPwr_kW
              REC_RTE_R_ComM_BSBatVltHlResInfo_tec_ComM_BSBatVltHlResInfo: accessed-variable=RTE_R_ComM_BSBatVltHlResInfo.tec_ComM_BSBatVltHlResInfo
              REC_RTE_R_ComM_BSBattSOC_pct_tec_ComM_BSBattSOC_pct: accessed-variable=RTE_R_ComM_BSBattSOC_pct.tec_ComM_BSBattSOC_pct
              REC_RTE_R_ComM_TriggerASWMsgReqInfo_tec_ComM_TriggerASWMsgReqInfo: accessed-variable=RTE_R_ComM_TriggerASWMsgReqInfo.tec_ComM_TriggerASWMsgReqInfo
              REC_RTE_R_LvMgmt_AppNMReqInfo_tec_LvMgmt_AppNMReqInfo: accessed-variable=RTE_R_LvMgmt_AppNMReqInfo.tec_LvMgmt_AppNMReqInfo
              REC_RTE_R_ComM_BSBatCrnt_tec_ComM_BSBatCrnt: accessed-variable=RTE_R_ComM_BSBatCrnt.tec_ComM_BSBatCrnt
              REC_RTE_R_LvMgmt_IndicatorLightStsInfo_tec_LvMgmt_IndicatorLightStsInfo: accessed-variable=RTE_R_LvMgmt_IndicatorLightStsInfo.tec_LvMgmt_IndicatorLightStsInfo
              REC_RTE_R_RngEstimn_MilgLowRmn_tec_RngEstimn_MilgLowRmn: accessed-variable=RTE_R_RngEstimn_MilgLowRmn.tec_RngEstimn_MilgLowRmn
              REC_RTE_R_ComM_BSHCrnt_tec_ComM_BSHCrnt: accessed-variable=RTE_R_ComM_BSHCrnt.tec_ComM_BSHCrnt
              REC_RTE_R_ComM_BSQuiescentCurrent_tec_ComM_BSQuiescentCurrent: accessed-variable=RTE_R_ComM_BSQuiescentCurrent.tec_ComM_BSQuiescentCurrent
          data-send-points:
            5 x access:
              SEND_SG_VCU_02_SigGroup_SG_VCU_02_SigGroup: accessed-variable=SG_VCU_02_SigGroup.SG_VCU_02_SigGroup
              SEND_SG_VCU_HMIsignals_02_SigGroup_SG_VCU_HMIsignals_02_SigGroup: accessed-variable=SG_VCU_HMIsignals_02_SigGroup.SG_VCU_HMIsignals_02_SigGroup
              SEND_SG_VCU_PlugInChrgInfo_SigGroup_SG_VCU_PlugInChrgInfo_SigGroup: accessed-variable=SG_VCU_PlugInChrgInfo_SigGroup.SG_VCU_PlugInChrgInfo_SigGroup
              SEND_SG_VCU_HMIsignals_01_SigGroup_SG_VCU_HMIsignals_01_SigGroup: accessed-variable=SG_VCU_HMIsignals_01_SigGroup.SG_VCU_HMIsignals_01_SigGroup
              SEND_SG_VCU_HMIsignals_03_SigGroup_1_SG_VCU_HMIsignals_03_SigGroup: accessed-variable=SG_VCU_HMIsignals_03_SigGroup_1.SG_VCU_HMIsignals_03_SigGroup
  swc implementation CtAp_CANHandler_Implementation: behavior=CtAp_CANHandler_InternalBehavior
    code-descriptors:
      code Default: artifact-descriptors=autosar-engineering-object=category=SWOBJ
